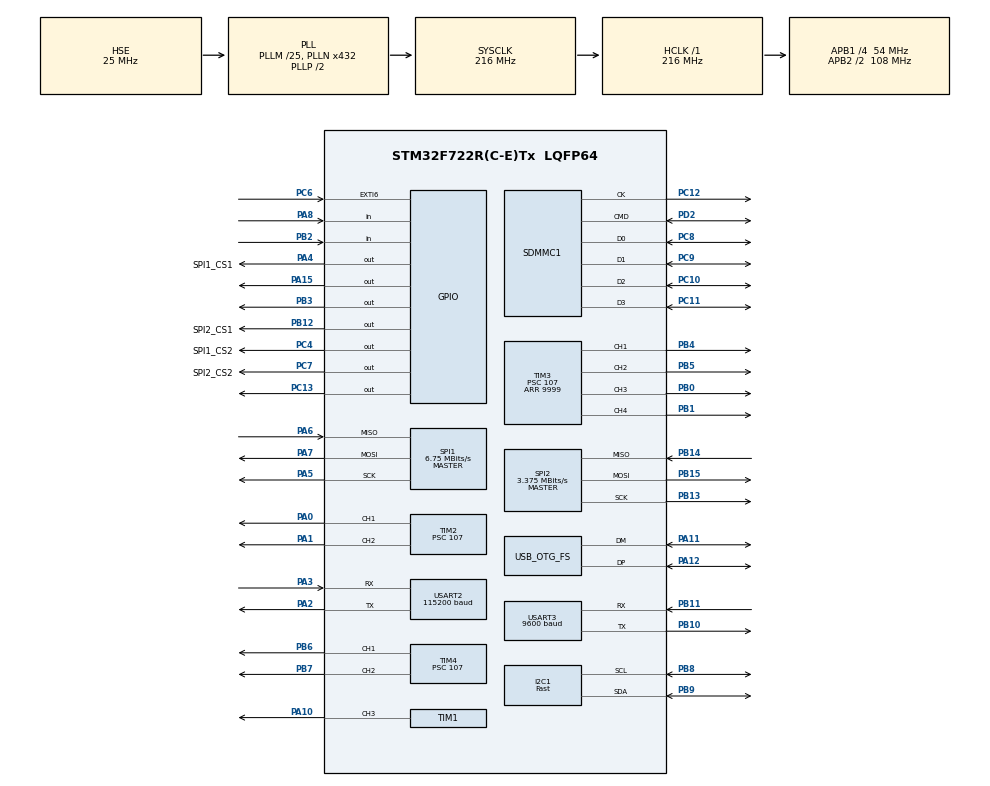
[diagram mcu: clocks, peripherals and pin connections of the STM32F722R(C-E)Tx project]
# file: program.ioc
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ADC1.Channel-13\#ChannelRegularConversion=ADC_CHANNEL_TEMPSENSOR
ADC1.NbrOfConversionFlag=1
ADC1.Rank-13\#ChannelRegularConversion=1
ADC1.SamplingTime-13\#ChannelRegularConversion=ADC_SAMPLETIME_3CYCLES
ADC1.master=1
CORTEX_M7.default_mode_Activation=1
Dma.I2C1_RX.1.Direction=DMA_PERIPH_TO_MEMORY
Dma.I2C1_RX.1.FIFOMode=DMA_FIFOMODE_DISABLE
Dma.I2C1_RX.1.Instance=DMA1_Stream0
Dma.I2C1_RX.1.MemDataAlignment=DMA_MDATAALIGN_BYTE
Dma.I2C1_RX.1.MemInc=DMA_MINC_ENABLE
Dma.I2C1_RX.1.Mode=DMA_NORMAL
Dma.I2C1_RX.1.PeriphDataAlignment=DMA_PDATAALIGN_BYTE
Dma.I2C1_RX.1.PeriphInc=DMA_PINC_DISABLE
Dma.I2C1_RX.1.Priority=DMA_PRIORITY_MEDIUM
Dma.I2C1_TX.7.Direction=DMA_MEMORY_TO_PERIPH
Dma.I2C1_TX.7.FIFOMode=DMA_FIFOMODE_DISABLE
Dma.I2C1_TX.7.Instance=DMA1_Stream7
Dma.I2C1_TX.7.MemDataAlignment=DMA_MDATAALIGN_BYTE
Dma.I2C1_TX.7.MemInc=DMA_MINC_ENABLE
Dma.I2C1_TX.7.Mode=DMA_NORMAL
Dma.I2C1_TX.7.PeriphDataAlignment=DMA_PDATAALIGN_BYTE
Dma.I2C1_TX.7.PeriphInc=DMA_PINC_DISABLE
Dma.I2C1_TX.7.Priority=DMA_PRIORITY_MEDIUM
Dma.Request0=SDMMC1
Dma.Request1=I2C1_RX
Dma.Request2=SPI1_RX
Dma.Request3=SPI2_RX
Dma.Request4=USART2_TX
Dma.Request5=SPI1_TX
Dma.Request6=SPI2_TX
Dma.Request7=I2C1_TX
Dma.SDMMC1.0.Direction=DMA_PERIPH_TO_MEMORY
Dma.SDMMC1.0.FIFOMode=DMA_FIFOMODE_ENABLE
Dma.SDMMC1.0.FIFOThreshold=DMA_FIFO_THRESHOLD_FULL
Dma.SDMMC1.0.Instance=DMA2_Stream6
Dma.SDMMC1.0.MemBurst=DMA_MBURST_INC4
Dma.SDMMC1.0.MemDataAlignment=DMA_MDATAALIGN_WORD
Dma.SDMMC1.0.MemInc=DMA_MINC_ENABLE
Dma.SDMMC1.0.Mode=DMA_PFCTRL
Dma.SDMMC1.0.PeriphBurst=DMA_PBURST_INC4
Dma.SDMMC1.0.PeriphDataAlignment=DMA_PDATAALIGN_WORD
Dma.SDMMC1.0.PeriphInc=DMA_PINC_DISABLE
Dma.SDMMC1.0.Priority=DMA_PRIORITY_LOW
Dma.SPI1_RX.2.Direction=DMA_PERIPH_TO_MEMORY
Dma.SPI1_RX.2.FIFOMode=DMA_FIFOMODE_DISABLE
Dma.SPI1_RX.2.Instance=DMA2_Stream0
Dma.SPI1_RX.2.MemDataAlignment=DMA_MDATAALIGN_BYTE
Dma.SPI1_RX.2.MemInc=DMA_MINC_ENABLE
Dma.SPI1_RX.2.Mode=DMA_NORMAL
Dma.SPI1_RX.2.PeriphDataAlignment=DMA_PDATAALIGN_BYTE
Dma.SPI1_RX.2.PeriphInc=DMA_PINC_DISABLE
Dma.SPI1_RX.2.Priority=DMA_PRIORITY_MEDIUM
Dma.SPI1_TX.5.Direction=DMA_MEMORY_TO_PERIPH
Dma.SPI1_TX.5.FIFOMode=DMA_FIFOMODE_DISABLE
Dma.SPI1_TX.5.Instance=DMA2_Stream5
Dma.SPI1_TX.5.MemDataAlignment=DMA_MDATAALIGN_BYTE
Dma.SPI1_TX.5.MemInc=DMA_MINC_ENABLE
Dma.SPI1_TX.5.Mode=DMA_NORMAL
Dma.SPI1_TX.5.PeriphDataAlignment=DMA_PDATAALIGN_BYTE
Dma.SPI1_TX.5.PeriphInc=DMA_PINC_DISABLE
Dma.SPI1_TX.5.Priority=DMA_PRIORITY_MEDIUM
Dma.SPI2_RX.3.Direction=DMA_PERIPH_TO_MEMORY
Dma.SPI2_RX.3.FIFOMode=DMA_FIFOMODE_DISABLE
Dma.SPI2_RX.3.Instance=DMA1_Stream3
Dma.SPI2_RX.3.MemDataAlignment=DMA_MDATAALIGN_BYTE
Dma.SPI2_RX.3.MemInc=DMA_MINC_ENABLE
Dma.SPI2_RX.3.Mode=DMA_NORMAL
Dma.SPI2_RX.3.PeriphDataAlignment=DMA_PDATAALIGN_BYTE
Dma.SPI2_RX.3.PeriphInc=DMA_PINC_DISABLE
Dma.SPI2_RX.3.Priority=DMA_PRIORITY_HIGH
Dma.SPI2_TX.6.Direction=DMA_MEMORY_TO_PERIPH
Dma.SPI2_TX.6.FIFOMode=DMA_FIFOMODE_DISABLE
Dma.SPI2_TX.6.Instance=DMA1_Stream4
Dma.SPI2_TX.6.MemDataAlignment=DMA_MDATAALIGN_BYTE
Dma.SPI2_TX.6.MemInc=DMA_MINC_ENABLE
Dma.SPI2_TX.6.Mode=DMA_NORMAL
Dma.SPI2_TX.6.PeriphDataAlignment=DMA_PDATAALIGN_BYTE
Dma.SPI2_TX.6.PeriphInc=DMA_PINC_DISABLE
Dma.SPI2_TX.6.Priority=DMA_PRIORITY_HIGH
Dma.USART2_TX.4.Direction=DMA_MEMORY_TO_PERIPH
Dma.USART2_TX.4.FIFOMode=DMA_FIFOMODE_DISABLE
Dma.USART2_TX.4.Instance=DMA1_Stream6
Dma.USART2_TX.4.MemDataAlignment=DMA_MDATAALIGN_BYTE
Dma.USART2_TX.4.MemInc=DMA_MINC_ENABLE
Dma.USART2_TX.4.Mode=DMA_NORMAL
Dma.USART2_TX.4.PeriphDataAlignment=DMA_PDATAALIGN_BYTE
Dma.USART2_TX.4.PeriphInc=DMA_PINC_DISABLE
Dma.USART2_TX.4.Priority=DMA_PRIORITY_MEDIUM
FATFS.BSP.number=1
FATFS0.BSP.STBoard=false
FATFS0.BSP.api=Unknown
FATFS0.BSP.instance=PA8
FATFS0.BSP.ip=GPIO
FATFS0.BSP.mode=Input
FATFS0.BSP.name=Detect_SDIO
FATFS0.BSP.solution=PA8
FREERTOS.BinarySemaphores01=icmDmaSem,Dynamic,NULL,Depleted;bmpDmaSem,Dynamic,NULL,Depleted;bmmDmaSem,Dynamic,NULL,Depleted;inaDmaSem,Dynamic,NULL,Depleted;flashDmaSem,Dynamic,NULL,Depleted;uart2TxDmaSem,Dynamic,NULL,Depleted;uart2RxSem,Dynamic,NULL,Depleted;pmwDmaSem,Dynamic,NULL,Depleted;i2c1DmaSem,Dynamic,NULL,Depleted
FREERTOS.Mutexes01=stateMutex,Dynamic,NULL,Available;spi1Mutex,Dynamic,NULL,Available;comTxMutex,Dynamic,NULL,Available;spi2Mutex,Dynamic,NULL,Available;i2c1Mutex,Dynamic,NULL,Available
FREERTOS.Queues01=loggerQueue,16,flight_log_t,0,Dynamic,NULL,NULL;telemetryQueue,4,telemetry_packet_t,0,Dynamic,NULL,NULL;transferQueue,1,uint8_t,0,Dynamic,NULL,NULL
FREERTOS.Tasks01=controlTask,48,2048,ControlTask,Default,NULL,Dynamic,NULL,NULL;commandTask,40,512,CommandTask,Default,NULL,Dynamic,NULL,NULL;loggerTask,32,256,LoggerTask,Default,NULL,Dynamic,NULL,NULL;telemetryTask,24,256,TelemetryTask,Default,NULL,Dynamic,NULL,NULL;transferTask,48,1024,TransferTask,Default,NULL,Dynamic,NULL,NULL
FREERTOS.configTOTAL_HEAP_SIZE=24576
FREERTOS.configUSE_NEWLIB_REENTRANT=1
I2C1.I2C_Speed_Mode=I2C_Fast
I2C1.Timing=0x6000030D
Mcu.Family=STM32F7
Mcu.Name=STM32F722R(C-E)Tx
Mcu.Package=LQFP64
NVIC.DMA1_Stream0_IRQn=true\:5\:0\:false\:false\:true\:true\:false\:true\:true
NVIC.DMA1_Stream3_IRQn=true\:5\:0\:false\:false\:true\:true\:false\:true\:true
NVIC.DMA1_Stream4_IRQn=true\:5\:0\:false\:false\:true\:true\:false\:true\:true
NVIC.DMA1_Stream6_IRQn=true\:5\:0\:false\:false\:true\:true\:false\:true\:true
NVIC.DMA1_Stream7_IRQn=true\:5\:0\:false\:false\:true\:true\:false\:true\:true
NVIC.DMA2_Stream0_IRQn=true\:5\:0\:false\:false\:true\:true\:false\:true\:true
NVIC.DMA2_Stream5_IRQn=true\:5\:0\:false\:false\:true\:true\:false\:true\:true
NVIC.DMA2_Stream6_IRQn=true\:5\:0\:false\:false\:true\:true\:false\:true\:true
NVIC.I2C1_ER_IRQn=true\:5\:0\:false\:false\:true\:true\:true\:true\:true
NVIC.I2C1_EV_IRQn=true\:5\:0\:false\:false\:true\:true\:true\:true\:true
NVIC.OTG_FS_IRQn=true\:5\:0\:false\:false\:true\:true\:false\:true\:true
NVIC.PriorityGroup=NVIC_PRIORITYGROUP_4
NVIC.SDMMC1_IRQn=true\:5\:0\:false\:false\:true\:true\:true\:true\:true
NVIC.SPI1_IRQn=true\:5\:0\:false\:false\:true\:true\:true\:true\:true
NVIC.SPI2_IRQn=true\:5\:0\:false\:false\:true\:true\:true\:true\:true
NVIC.TIM6_DAC_IRQn=true\:5\:0\:false\:false\:true\:true\:true\:true\:true
NVIC.TIM7_IRQn=true\:15\:0\:false\:false\:true\:false\:false\:true\:true
NVIC.TimeBase=TIM7_IRQn
NVIC.TimeBaseIP=TIM7
NVIC.USART2_IRQn=true\:5\:0\:false\:false\:true\:true\:true\:true\:true
PA0-WKUP.Signal=S_TIM2_CH1_ETR
PA1.Signal=S_TIM2_CH2
PA10.Signal=S_TIM1_CH3
PA11.Mode=Device_Only
PA11.Signal=USB_OTG_FS_DM
PA12.Mode=Device_Only
PA12.Signal=USB_OTG_FS_DP
PA13.Mode=Serial_Wire
PA13.Signal=SYS_JTMS-SWDIO
PA14.Mode=Serial_Wire
PA14.Signal=SYS_JTCK-SWCLK
PA15.Signal=GPIO_Output
PA2.Mode=Asynchronous
PA2.Signal=USART2_TX
PA3.Mode=Asynchronous
PA3.Signal=USART2_RX
PA4.GPIO_Label=SPI1_CS1
PA4.GPIO_Speed=GPIO_SPEED_FREQ_HIGH
PA4.PinState=GPIO_PIN_SET
PA4.Signal=GPIO_Output
PA5.Mode=Full_Duplex_Master
PA5.Signal=SPI1_SCK
PA6.Mode=Full_Duplex_Master
PA6.Signal=SPI1_MISO
PA7.Mode=Full_Duplex_Master
PA7.Signal=SPI1_MOSI
PA8.Signal=GPIO_Input
PB0.Signal=S_TIM3_CH3
PB1.Signal=S_TIM3_CH4
PB10.Mode=Asynchronous
PB10.Signal=USART3_TX
PB11.Mode=Asynchronous
PB11.Signal=USART3_RX
PB12.GPIO_Label=SPI2_CS1
PB12.GPIO_Speed=GPIO_SPEED_FREQ_HIGH
PB12.PinState=GPIO_PIN_SET
PB12.Signal=GPIO_Output
PB13.Mode=Full_Duplex_Master
PB13.Signal=SPI2_SCK
PB14.Mode=Full_Duplex_Master
PB14.Signal=SPI2_MISO
PB15.Mode=Full_Duplex_Master
PB15.Signal=SPI2_MOSI
PB2.Signal=GPIO_Input
PB3.Signal=GPIO_Output
PB4.Signal=S_TIM3_CH1
PB5.Signal=S_TIM3_CH2
PB6.Signal=S_TIM4_CH1
PB7.Signal=S_TIM4_CH2
PB8.Mode=I2C
PB8.Signal=I2C1_SCL
PB9.Mode=I2C
PB9.Signal=I2C1_SDA
PC10.Mode=SD_4_bits_Wide_bus
PC10.Signal=SDMMC1_D2
PC11.Mode=SD_4_bits_Wide_bus
PC11.Signal=SDMMC1_D3
PC12.Mode=SD_4_bits_Wide_bus
PC12.Signal=SDMMC1_CK
PC13.Signal=GPIO_Output
PC4.GPIO_Label=SPI1_CS2
PC4.GPIO_Speed=GPIO_SPEED_FREQ_HIGH
PC4.PinState=GPIO_PIN_SET
PC4.Signal=GPIO_Output
PC6.Signal=GPXTI6
PC7.GPIO_Label=SPI2_CS2
PC7.GPIO_Speed=GPIO_SPEED_FREQ_HIGH
PC7.PinState=GPIO_PIN_SET
PC7.Signal=GPIO_Output
PC8.Mode=SD_4_bits_Wide_bus
PC8.Signal=SDMMC1_D0
PC9.Mode=SD_4_bits_Wide_bus
PC9.Signal=SDMMC1_D1
PD2.Mode=SD_4_bits_Wide_bus
PD2.Signal=SDMMC1_CMD
PH0-OSC_IN.Mode=HSE-External-Oscillator
PH0-OSC_IN.Signal=RCC_OSC_IN
PH1-OSC_OUT.Mode=HSE-External-Oscillator
PH1-OSC_OUT.Signal=RCC_OSC_OUT
ProjectManager.HeapSize=0x1000
ProjectManager.StackSize=0x800
ProjectManager.TargetToolchain=STM32CubeIDE
RCC.AHBFreq_Value=216000000
RCC.APB1CLKDivider=RCC_HCLK_DIV4
RCC.APB1Freq_Value=54000000
RCC.APB1TimFreq_Value=108000000
RCC.APB2CLKDivider=RCC_HCLK_DIV2
RCC.APB2Freq_Value=108000000
RCC.APB2TimFreq_Value=216000000
RCC.CortexFreq_Value=216000000
RCC.HCLKFreq_Value=216000000
RCC.HSE_VALUE=25000000
RCC.HSI_VALUE=16000000
RCC.LSE_VALUE=32768
RCC.PLLM=25
RCC.PLLN=432
RCC.PLLQ=9
RCC.SDMMCClockSelection=RCC_SDMMC1CLKSOURCE_CLK48
RCC.SYSCLKFreq_VALUE=216000000
RCC.SYSCLKSource=RCC_SYSCLKSOURCE_PLLCLK
RCC.USBFreq_Value=48000000
RCC.VCOOutputFreq_Value=432000000
SDMMC1.ClockDiv=1
SDMMC1.HardwareFlowControl=SDMMC_HARDWARE_FLOW_CONTROL_ENABLE
SH.S_TIM1_CH3.0=TIM1_CH3,PWM Generation3 CH3
SH.S_TIM2_CH1_ETR.0=TIM2_CH1,PWM Generation1 CH1
SH.S_TIM2_CH2.0=TIM2_CH2,PWM Generation2 CH2
SH.S_TIM3_CH1.0=TIM3_CH1,PWM Generation1 CH1
SH.S_TIM3_CH2.0=TIM3_CH2,PWM Generation2 CH2
SH.S_TIM3_CH3.0=TIM3_CH3,PWM Generation3 CH3
SH.S_TIM3_CH4.0=TIM3_CH4,PWM Generation4 CH4
SH.S_TIM4_CH1.0=TIM4_CH1,PWM Generation1 CH1
SH.S_TIM4_CH2.0=TIM4_CH2,PWM Generation2 CH2
SPI1.BaudRatePrescaler=SPI_BAUDRATEPRESCALER_16
SPI1.CLKPhase=SPI_PHASE_2EDGE
SPI1.CLKPolarity=SPI_POLARITY_HIGH
SPI1.CalculateBaudRate=6.75 MBits/s
SPI1.DataSize=SPI_DATASIZE_8BIT
SPI1.Direction=SPI_DIRECTION_2LINES
SPI1.Mode=SPI_MODE_MASTER
SPI1.VirtualType=VM_MASTER
SPI2.BaudRatePrescaler=SPI_BAUDRATEPRESCALER_16
SPI2.CLKPhase=SPI_PHASE_1EDGE
SPI2.CLKPolarity=SPI_POLARITY_LOW
SPI2.CalculateBaudRate=3.375 MBits/s
SPI2.DataSize=SPI_DATASIZE_8BIT
SPI2.Direction=SPI_DIRECTION_2LINES
SPI2.Mode=SPI_MODE_MASTER
SPI2.VirtualType=VM_MASTER
TIM1.Channel-PWM\ Generation3\ CH3=TIM_CHANNEL_3
TIM1.Period=19999
TIM1.Prescaler=107
TIM2.Channel-PWM\ Generation1\ CH1=TIM_CHANNEL_1
TIM2.Channel-PWM\ Generation2\ CH2=TIM_CHANNEL_2
TIM2.OCFastMode_PWM-PWM\ Generation1\ CH1=TIM_OCFAST_DISABLE
TIM2.Period=2499
TIM2.Prescaler=107
TIM3.Channel-PWM\ Generation1\ CH1=TIM_CHANNEL_1
TIM3.Channel-PWM\ Generation2\ CH2=TIM_CHANNEL_2
TIM3.Channel-PWM\ Generation3\ CH3=TIM_CHANNEL_3
TIM3.Channel-PWM\ Generation4\ CH4=TIM_CHANNEL_4
TIM3.OCFastMode_PWM-PWM\ Generation1\ CH1=TIM_OCFAST_DISABLE
TIM3.Period=9999
TIM3.Prescaler=107
TIM4.Channel-PWM\ Generation1\ CH1=TIM_CHANNEL_1
TIM4.Channel-PWM\ Generation2\ CH2=TIM_CHANNEL_2
TIM4.OCFastMode_PWM-PWM\ Generation1\ CH1=TIM_OCFAST_DISABLE
TIM4.Period=19999
TIM4.Prescaler=107
TIM6.Period=9999
TIM6.Prescaler=107
USART2.BaudRate=115200
USART2.VirtualMode-Asynchronous=VM_ASYNC
USART3.BaudRate=9600
USART3.VirtualMode-Asynchronous=VM_ASYNC
USB_DEVICE.CLASS_NAME_FS=CDC
USB_DEVICE.VirtualMode-CDC_FS=Cdc
USB_DEVICE.VirtualModeFS=Cdc_FS
USB_OTG_FS.VirtualMode=Device_Only
USB_OTG_FS.battery_charging_enable=DISABLE
VP_ADC1_TempSens_Input.Mode=IN-TempSens
VP_ADC1_Vref_Input.Mode=IN-Vrefint
VP_FATFS_VS_SDIO.Mode=SDIO
VP_FREERTOS_VS_CMSIS_V2.Mode=CMSIS_V2
VP_SYS_VS_tim7.Mode=TIM7
VP_TIM2_VS_ClockSourceINT.Mode=Internal
VP_TIM3_VS_ClockSourceINT.Mode=Internal
VP_TIM4_VS_ClockSourceINT.Mode=Internal
VP_TIM6_VS_ClockSourceINT.Mode=Enable_Timer
VP_USB_DEVICE_VS_USB_DEVICE_CDC_FS.Mode=CDC_FS
board=custom

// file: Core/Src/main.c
/* USER CODE BEGIN Header */
/**
  ******************************************************************************
  * @file           : main.c
  * @brief          : Main program body
  ******************************************************************************
  * @attention
  *
  * Copyright (c) 2026 STMicroelectronics.
  * All rights reserved.
  *
  * This software is licensed under terms that can be found in the LICENSE file
  * in the root directory of this software component.
  * If no LICENSE file comes with this software, it is provided AS-IS.
  *
  ******************************************************************************
  */
/* USER CODE END Header */
#include "main.h"
#include "cmsis_os.h"
#include "adc.h"
#include "dma.h"
#include "fatfs.h"
#include "i2c.h"
#include "sdmmc.h"
#include "spi.h"
#include "tim.h"
#include "usart.h"
#include "usb_device.h"
#include "gpio.h"

/* USER CODE BEGIN Includes */
#include "global.h"
/* USER CODE END Includes */

/* USER CODE BEGIN PV */

#if 1 // GLOBAL VARIABLES
bmm150_data_t bmm150_data;
bmp388_data_t bmp388_data;
icm42688p_data_t icm42688p_data;
ina226_data_t ina226_data;
FATFS fs;
FIL fil;
FRESULT res;
uint8_t com_receive_buf[128] = {0};
uint8_t com_transmit_buf[128] = {0};
note_t melody[] = {
    {NOTE_C5, EIGHTH}, {NOTE_D5, EIGHTH}, {NOTE_E5, EIGHTH}, {NOTE_G5, EIGHTH},
    {NOTE_E5, EIGHTH}, {NOTE_G5, QUARTER}, {NOTE_C6, HALF},
};
uint8_t melody_len = (sizeof(melody) / sizeof(melody[0]));

FusionAhrs ahrs;
FusionBias bias;
FusionMatrix gyro_misalignment = {{1.0f, 0.0f, 0.0f, 0.0f, 1.0f, 0.0f, 0.0f, 0.0f, 1.0f}};
FusionVector gyro_sensitivity = {{1.0f, 1.0f, 1.0f}};
FusionVector gyro_offset = {{0.0f, 0.0f, 0.0f}};
FusionMatrix accel_misalignement = {{1.0f, 0.0f, 0.0f, 0.0f, 1.0f, 0.0f, 0.0f, 0.0f, 1.0f}};
FusionVector accel_sensitivity = {{1.0f, 1.0f, 1.0f}};
FusionVector accel_offset = {{0.0f, 0.0f, 0.0f}};
FusionMatrix mag_softIronMatrix = {{0.940f, 0.041f, 0.0f, 0.041f, 1.027f, 0.006f, 0.0f, 0.006f, 1.047f}};
FusionVector mag_hardIronOffset = {{-7.37f, 3.12f, 16.56f}};

FusionAhrsSettings settings = {
	.convention = FusionConventionNed,
	.gain = 0.5f,
	.gyroscopeRange = 500.0f,
	.accelerationRejection = 8.0f,
	.magneticRejection = 10.0f,
};
FusionVector gyro;
FusionVector accel;
FusionVector mag;
FusionEuler ori;
FusionVector lin_accel;
FusionVector vel = {{0, 0, 0}};
FusionVector pos = {{0, 0, 0}};

kalman_t kf_altitude;
float altitude_offset = 0;

lpf_t lpf_altitude;
lpf_t lpf_voltage;
lpf_t lpf_velx;
lpf_t lpf_vely;

lqr_t lqr;
float u_min[] = {-0.149066f, -0.149066f, -0.1, -HOVER_THRUST};
float u_max[] = { 0.149066f,  0.149066f, 0.1, 0.05f * G};
float x_ref[] = {0.0f, 0.0f, 0.0f, 0.0f, 0.0f, 0.0f, 0.0f, 0.0f, 0.0f, 0.0f, 0.0f, 0.0f};
float cmd_ref[] = {0.0f, 0.0f, 0.0f};
float pz_integral = 0;
float rx_integral = 0;
float ry_integral = 0;
float rz_integral = 0;
float rz_offset = 0;
float rz_prev_wrapped = 0.0f;
float rz_unwrapped = 0.0f;
volatile bool rz_unwrap_init = false;
volatile bool dt_init = false;

float ref_rx_offset = -4.0f; // hard coded offsets
float ref_ry_offset = 7.0f;  // hard coded offsets
float ref_rz_offset = 0;
float ref_pz_offset = 0;

volatile spi2_pending_t spi2_pending = SPI2_PENDING_NONE;
volatile i2c1_pending_t i2c1_pending = I2C1_PENDING_NONE;

drone_state_t drone_state = DRONE_DISARMED;

uint32_t flash_write_address = 0x000000;
uint32_t flash_max_address = 0x1000000;
#endif // GLOBAL VARIABLES

#if 1 // LOCAL VARIABLES
uint16_t flash_buf_idx = 0;
uint8_t  flash_page_buffer[256];
const float K[LQR_MAX_INPUTS][LQR_MAX_STATES] = {
    {-1.14198845f, 0.00000000f, 0.00000000f, 0.00000000f, -0.29207114f, 0.00000000f, 0.00000000f, 0.00000000f, -0.29505944f, 0.00000000f, 0.00000000f, 0.00000000f},
    {0.00000000f, 1.14198845f, 0.00000000f, 0.00000000f, 0.00000000f, 0.29207114f, 0.00000000f, 0.00000000f, 0.00000000f, 0.29505944f, 0.00000000f, 0.00000000f},
    {0.00000000f, 0.00000000f, 0.06454058f, 0.00000000f, 0.00000000f, 0.00000000f, 0.57378372f, 0.00000000f, 0.00000000f, 0.00000000f, 0.00238777f, 0.00000000f},
	{0.00000000f, 0.00000000f, 0.00000000f, 1.73874813f, 0.00000000f, 0.00000000f, 0.00000000f, 1.23067720f, 0.00000000f, 0.00000000f, 0.00000000f, 0.04408133f},
};
float  Q[] = {0.05f, // acceleration
             0.1f, // velocity
             0.3f}; // position

float R[] = {0.15f, // imu noise
             0.15f, // barometer noise
			 0.005f}; // tof noise

kalman_t kf_vel_x;
kalman_t kf_vel_y;

float Q_vel[] = {0.05f,  // acceleration — reused from kf_altitude's tuning, same physical sensor
                  0.5f}; // velocity

float R_vel[] = {0.15f, // accelerometer noise
                  0.001f}; // optical flow sensor noise

float x0_vel[] = {0.0f, 0.0f};

pid_t vel_pid_x = {
	.kp =  -0.140f,
	.ki = -0.040f,
	.kd = -0.008f,
	.output_min = -0.2f,
	.output_max =  0.2f,
	.integral_min = -2.5f,
	.integral_max =  2.5f,
	.d_filter_alpha = 0.1f,
	.decimation_factor = 5, // division factor from the P and I update loop to the output loop
};
pid_t vel_pid_y = {
	.kp =  0.140f,
	.ki = 0.040f,
	.kd = 0.008f,
	.output_min = -0.2f,
	.output_max =  0.2f,
	.integral_min = -2.5f,
	.integral_max =  2.5f,
	.d_filter_alpha = 0.1f,
	.decimation_factor = 5,
};
pid_t pos_p_x = {
	.kp =  0.5f,
	.output_min = -0.5f,
	.output_max =  0.5f,
	.decimation_factor = 10, // division factor from the P and I update loop to the output loop
};

pid_t pos_p_y = {
	.kp =  0.5f,
	.output_min = -0.5f,
	.output_max =  0.5f,
	.decimation_factor = 10,
};
float x0[] = {0.0f, 0.0f, 0.0f};
#endif // LOCAL VARIABLES

#if 1 // DRIVER CONFIG
pmw3901_data_t pmw3901_data;
pmw3901_config_t pmw3901_conf = {
    .hspi    = &hspi2,
    .cs_port = SPI2_CS2_GPIO_Port,
    .cs_pin  = SPI2_CS2_Pin,
};

uint16_t vl53l1x_dev = 0x52;
servo_config_t servox_conf = {
	.pwm_timer = &htim3,
	.pwm_channel = TIM_CHANNEL_1,
	.offset = 25,
};
servo_config_t servoy_conf = {
	.pwm_timer = &htim3,
	.pwm_channel = TIM_CHANNEL_4,
	.offset = 20,
};
motor_config_t motor1_conf = {
	.pwm_timer = &htim2,
	.pwm_channel = TIM_CHANNEL_1,
};
motor_config_t motor2_conf = {
	.pwm_timer = &htim2,
	.pwm_channel = TIM_CHANNEL_2,
};
bmm150_config_t bmm150_conf = {
	.iface    = BMM150_IFACE_I2C,
	.hi2c     = &hi2c1,
	.i2c_addr = BMM150_I2C_ADDR_ALT3,
	.hspi     = NULL,
	.cs_port  = NULL,
	.cs_pin   = 0,
	.op_ctrl  = BMM150_OPMODE_NORMAL | BMM150_ODR_10HZ,
	.rep_xy   = 0x01U,
	.rep_z    = 0x06U,
};
bmp388_config_t bmp388_conf = {
    .iface    = BMP388_IFACE_SPI,
    .hspi     = &hspi1,
    .cs_port  = SPI1_CS1_GPIO_Port,
    .cs_pin   = SPI1_CS1_Pin,
    .prs_cfg  = BMP388_ODR_50HZ | BMP388_OSR_x8,
    .tmp_cfg  = BMP388_ODR_50HZ | BMP388_OSR_x1,
    .mode     = BMP388_MODE_NORMAL,
    .sea_level_hpa = 1013.25f,
};
icm42688p_config_t icm42688p_conf = {
    .iface         = ICM42688P_IFACE_SPI,
    .hspi          = &hspi2,
    .cs_port       = SPI2_CS1_GPIO_Port,
    .cs_pin        = SPI2_CS1_Pin,
    .hi2c          = NULL,
    .i2c_addr      = 0,
    .gyro_config  = ICM42688P_GYRO_FS_500DPS  | ICM42688P_ODR_1760HZ,
    .accel_config = ICM42688P_ACCEL_FS_8G     | ICM42688P_ODR_1760HZ,
    .acc_scale     = ICM42688P_ACC_SCALE_8G,
    .gyro_scale    = ICM42688P_GYRO_SCALE_500DPS,
};
ina226_config_t ina226_conf = {
	.hi2c          = &hi2c1,
	.i2c_addr      = INA226_I2C_ADDR(0, 0),
	.config_reg    = (INA226_AVG_1 | INA226_VBUS_CT_140US | INA226_VSH_CT_140US | INA226_MODE_SHUNT_BUS_CONT),
	.current_lsb_A = 0.001f,
	.r_shunt_ohm   = 0.002f
};
w25q128_config_t w25q128_conf = {
	.hspi    = &hspi1,
	.cs_port = SPI1_CS2_GPIO_Port,
	.cs_pin  = SPI1_CS2_Pin
};
com_config_t com_conf = {
	.com_method = COM_LORA,
	.m0m1_pin = GPIO_PIN_3,
	.m0m1_port = GPIOB,
	.uart    = &huart2,
	.receive_buf = com_receive_buf,
	.transmit_buf = com_transmit_buf,
	.timeout = 1000,
};
signal_config_t signal_conf = {
	.led_port = GPIOC,
	.led_pin = GPIO_PIN_13,
	.buzzer_htim = &htim1,
	.buzzer_channel = TIM_CHANNEL_3,
};
#endif // DRIVER CONFIG

/* USER CODE END PV */

void SystemClock_Config(void);
static void MPU_Config(void);
void MX_FREERTOS_Init(void);

/* USER CODE BEGIN 0 */
static uint32_t g_log_field_mask = LOG_MASK_ALL;

static uint16_t flight_log_serialize(uint8_t *buf, const flight_log_t *log, uint32_t mask) {
	uint16_t idx = 0;
	memcpy(&buf[idx], &mask, 4); idx += 4;
	memcpy(&buf[idx], &log->timestamp_ms, 4); idx += 4;
	buf[idx++] = log->drone_state;

	if (mask & LOG_FIELD_ACCEL)   { memcpy(&buf[idx], &log->accel, sizeof(FusionVector)); idx += sizeof(FusionVector); }
	if (mask & LOG_FIELD_GYRO)    { memcpy(&buf[idx], &log->gyro,  sizeof(FusionVector)); idx += sizeof(FusionVector); }
	if (mask & LOG_FIELD_MAG)     { memcpy(&buf[idx], &log->mag,   sizeof(FusionVector)); idx += sizeof(FusionVector); }
	if (mask & LOG_FIELD_BARO)    { memcpy(&buf[idx], &log->baro_altitude_m, 4); idx += 4; }
	if (mask & LOG_FIELD_TOF)     { memcpy(&buf[idx], &log->tof_altitude_m,  4); idx += 4; }
	if (mask & LOG_FIELD_FLOW)    { memcpy(&buf[idx], &log->flow_dx, 4); idx += 4;
	                                 memcpy(&buf[idx], &log->flow_dy, 4); idx += 4; }
	if (mask & LOG_FIELD_VOLTAGE) { memcpy(&buf[idx], &log->voltage, 4); idx += 4; }
	if (mask & LOG_FIELD_ORI) {
		memcpy(&buf[idx], &log->rx, 4); idx += 4;
		memcpy(&buf[idx], &log->ry, 4); idx += 4;
		memcpy(&buf[idx], &log->rz, 4); idx += 4;
	}
	if (mask & LOG_FIELD_POS) {
		memcpy(&buf[idx], &log->pos_x, 4); idx += 4;
		memcpy(&buf[idx], &log->pos_y, 4); idx += 4;
		memcpy(&buf[idx], &log->pos_z, 4); idx += 4;
	}
	if (mask & LOG_FIELD_POS_P)   { memcpy(&buf[idx], &log->pos_p_out_x, 4); idx += 4;
	                                 memcpy(&buf[idx], &log->pos_p_out_y, 4); idx += 4; }
	if (mask & LOG_FIELD_VEL_PID) { memcpy(&buf[idx], &log->vel_pid_out_x, 4); idx += 4;
	                                 memcpy(&buf[idx], &log->vel_pid_out_y, 4); idx += 4; }
	if (mask & LOG_FIELD_LQR)     { memcpy(&buf[idx], log->lqr_u, sizeof(log->lqr_u)); idx += sizeof(log->lqr_u); }
	if (mask & LOG_FIELD_SERVO)   { memcpy(&buf[idx], &log->servo_x, 4); idx += 4;
	                                 memcpy(&buf[idx], &log->servo_y, 4); idx += 4; }
	if (mask & LOG_FIELD_MOTOR)   { memcpy(&buf[idx], &log->motor1, 4); idx += 4;
	                                 memcpy(&buf[idx], &log->motor2, 4); idx += 4; }

	return idx;
}

/* Returns false if this record slot is erased/unwritten flash (end of valid
 * data in this page). Otherwise populates *out (fields absent from this
 * record's own mask are left zeroed) and *record_len (bytes consumed). */
static bool flight_log_deserialize(const uint8_t *buf, uint16_t buf_remaining, flight_log_t *out, uint16_t *record_len) {
	if (buf_remaining < 9) return false;

	uint32_t mask;
	memcpy(&mask, &buf[0], 4);
	if (mask == LOG_MASK_ERASED) return false;

	memset(out, 0, sizeof(*out));
	uint16_t idx = 4;
	memcpy(&out->timestamp_ms, &buf[idx], 4); idx += 4;
	out->drone_state = buf[idx++];

	if (mask & LOG_FIELD_ACCEL) { memcpy(&out->accel, &buf[idx], sizeof(FusionVector)); idx += sizeof(FusionVector); }
	if (mask & LOG_FIELD_GYRO)  { memcpy(&out->gyro,  &buf[idx], sizeof(FusionVector)); idx += sizeof(FusionVector); }
	if (mask & LOG_FIELD_MAG)   { memcpy(&out->mag,   &buf[idx], sizeof(FusionVector)); idx += sizeof(FusionVector); }
	if (mask & LOG_FIELD_BARO)  { memcpy(&out->baro_altitude_m, &buf[idx], 4); idx += 4; }
	if (mask & LOG_FIELD_TOF)   { memcpy(&out->tof_altitude_m,  &buf[idx], 4); idx += 4; }
	if (mask & LOG_FIELD_FLOW)  { memcpy(&out->flow_dx, &buf[idx], 4); idx += 4;
	                               memcpy(&out->flow_dy, &buf[idx], 4); idx += 4; }
	if (mask & LOG_FIELD_VOLTAGE) { memcpy(&out->voltage, &buf[idx], 4); idx += 4; }
	if (mask & LOG_FIELD_ORI) {
		memcpy(&out->rx, &buf[idx], 4); idx += 4;
		memcpy(&out->ry, &buf[idx], 4); idx += 4;
		memcpy(&out->rz, &buf[idx], 4); idx += 4;
	}
	if (mask & LOG_FIELD_POS) {
		memcpy(&out->pos_x, &buf[idx], 4); idx += 4;
		memcpy(&out->pos_y, &buf[idx], 4); idx += 4;
		memcpy(&out->pos_z, &buf[idx], 4); idx += 4;
	}
	if (mask & LOG_FIELD_POS_P)   { memcpy(&out->pos_p_out_x, &buf[idx], 4); idx += 4;
	                                 memcpy(&out->pos_p_out_y, &buf[idx], 4); idx += 4; }
	if (mask & LOG_FIELD_VEL_PID) { memcpy(&out->vel_pid_out_x, &buf[idx], 4); idx += 4;
	                                 memcpy(&out->vel_pid_out_y, &buf[idx], 4); idx += 4; }
	if (mask & LOG_FIELD_LQR)     { memcpy(out->lqr_u, &buf[idx], sizeof(out->lqr_u)); idx += sizeof(out->lqr_u); }
	if (mask & LOG_FIELD_SERVO)   { memcpy(&out->servo_x, &buf[idx], 4); idx += 4;
	                                 memcpy(&out->servo_y, &buf[idx], 4); idx += 4; }
	if (mask & LOG_FIELD_MOTOR)   { memcpy(&out->motor1, &buf[idx], 4); idx += 4;
	                                 memcpy(&out->motor2, &buf[idx], 4); idx += 4; }

	*record_len = idx;
	return true;
}

void log_to_flash(flight_log_t *log) {
	if (flash_write_address >= flash_max_address) {
		return;
	}

	uint8_t rec_buf[FLIGHT_LOG_MAX_RECORD_SIZE];
	uint16_t rec_len = flight_log_serialize(rec_buf, log, g_log_field_mask);

	if (flash_buf_idx + rec_len > 256) {
		memset(&flash_page_buffer[flash_buf_idx], 0xFF, 256 - flash_buf_idx);

		w25q128_data_t wdata = { .buf = flash_page_buffer, .len = 256 };
		if (w25q128_write_dma(flash_write_address, &wdata, flash_dma_complete_cb) == HAL_OK) {
			osSemaphoreAcquire(flashDmaSemHandle, W25Q128_TIMEOUT_PAGE_PROGRAM_MS);
		}
		w25q128_wait_busy(W25Q128_TIMEOUT_PAGE_PROGRAM_MS);

		flash_write_address += 256;
		flash_buf_idx = 0;

		if (flash_write_address >= flash_max_address) {
			return;
		}
	}

	memcpy(&flash_page_buffer[flash_buf_idx], rec_buf, rec_len);
	flash_buf_idx += rec_len;
}
uint8_t transfer_logs_to_sd(void) {
	uint32_t read_address = 0x000000;
	uint8_t read_page_buffer[256];
	flight_log_t log_packet;
	char csv_line[320];
	UINT bytes_written;

	if (flash_write_address == 0x000000 && flash_buf_idx == 0) {
		return 0;
	}

	res = f_mount(&fs, "", 1);
	if (res != FR_OK) {
		return 0;
	}

	res = f_open(&fil, "flight.csv", FA_WRITE | FA_CREATE_ALWAYS);
	if (res != FR_OK) {
		f_mount(NULL, "", 0);
		return 0;
	}

	const char* header =
		"timestamp_ms,state,"
		"accel_x,accel_y,accel_z,gyro_x,gyro_y,gyro_z,mag_x,mag_y,mag_z,"
		"baro_alt,tof_alt,flow_dx,flow_dy,voltage,"
		"rx,ry,rz,pos_x,pos_y,pos_z,"
		"pos_p_x,pos_p_y,vel_pid_x,vel_pid_y,"
		"lqr_u0,lqr_u1,lqr_u2,lqr_u3,"
		"servo_x,servo_y,motor1,motor2\n";
	res = f_write(&fil, header, strlen(header), &bytes_written);
	if (res != FR_OK || bytes_written != strlen(header)) {
		f_close(&fil);
		f_mount(NULL, "", 0);
		return 0;
	}

	if (flash_buf_idx > 0) {
		memset(&flash_page_buffer[flash_buf_idx], 0xFF, 256 - flash_buf_idx);

		if (w25q128_write(flash_write_address, flash_page_buffer, 256) != HAL_OK) {
			f_close(&fil);
			f_mount(NULL, "", 0);
			return 0;
		}
		w25q128_wait_busy(W25Q128_TIMEOUT_PAGE_PROGRAM_MS);
		flash_write_address += 256;
	}

	while (read_address < flash_write_address) {
		w25q128_data_t read_data = { .buf = read_page_buffer, .len = 256 };

		if (w25q128_read(read_address, &read_data) != HAL_OK) {
			break;
		}

		uint16_t offset = 0;
		while (offset < 256) {
			uint16_t record_len = 0;
			if (!flight_log_deserialize(&read_page_buffer[offset], 256 - offset, &log_packet, &record_len)) {
				break;   // erased/unwritten from here on within this page
			}

			int len = snprintf(csv_line, sizeof(csv_line),
				"%lu,%u,"
				"%.4f,%.4f,%.4f,%.4f,%.4f,%.4f,%.4f,%.4f,%.4f,"
				"%.3f,%.3f,%.3f,%.3f,%.3f,"
				"%.4f,%.4f,%.4f,%.3f,%.3f,%.3f,"
				"%.4f,%.4f,%.4f,%.4f,"
				"%.4f,%.4f,%.4f,%.4f,"
				"%.3f,%.3f,%.3f,%.3f\n",
				log_packet.timestamp_ms, log_packet.drone_state,
				log_packet.accel.axis.x, log_packet.accel.axis.y, log_packet.accel.axis.z,
				log_packet.gyro.axis.x,  log_packet.gyro.axis.y,  log_packet.gyro.axis.z,
				log_packet.mag.axis.x,   log_packet.mag.axis.y,   log_packet.mag.axis.z,
				log_packet.baro_altitude_m, log_packet.tof_altitude_m,
				log_packet.flow_dx, log_packet.flow_dy, log_packet.voltage,
				log_packet.rx, log_packet.ry, log_packet.rz,
				log_packet.pos_x, log_packet.pos_y, log_packet.pos_z,
				log_packet.pos_p_out_x, log_packet.pos_p_out_y,
				log_packet.vel_pid_out_x, log_packet.vel_pid_out_y,
				log_packet.lqr_u[0], log_packet.lqr_u[1], log_packet.lqr_u[2], log_packet.lqr_u[3],
				log_packet.servo_x, log_packet.servo_y, log_packet.motor1, log_packet.motor2);

			if (len > 0 && (size_t)len < sizeof(csv_line)) {
				f_write(&fil, csv_line, len, &bytes_written);
			}

			offset += record_len;
		}

		read_address += 256;
	}

	f_close(&fil);
	f_mount(NULL, "", 0);
	return 1;
}

void sys_init() {
	servo_init(&servox_conf);
	servo_init(&servoy_conf);
	motor_init(&motor1_conf);
	motor_init(&motor2_conf);
	com_init(&com_conf);
	com_receive_it_start(&com_conf);
	signal_init(&signal_conf);
	bmm150_init(&bmm150_conf);
	bmp388_init(&bmp388_conf);
	icm42688p_init(&icm42688p_conf);
	ina226_init(&ina226_conf);
	w25q128_init(&w25q128_conf);
	pmw3901_init(&pmw3901_conf);
	VL53L1X_SensorInit(vl53l1x_dev);
	VL53L1X_SetDistanceMode(vl53l1x_dev, 1); // distance mode 1:short, 2:long
	VL53L1X_SetTimingBudgetInMs(vl53l1x_dev, 20);
	VL53L1X_SetInterMeasurementInMs(vl53l1x_dev, 20);
	VL53L1X_StartRanging(vl53l1x_dev);

	FusionAhrsInitialise(&ahrs); // fusion initialization
	FusionAhrsSetSettings(&ahrs, &settings);
	FusionBiasInitialise(&bias);
	FusionBiasSettings bias_settings = fusionBiasDefaultSettings;
	bias_settings.sampleRate = 100;
	FusionBiasSetSettings(&bias, &bias_settings);

	// calibrate accelerometer & gyroscope
	int i = 0;
	int ITERATION = 30;

	FusionVector accel_sum = {0};
	for (i = 0; i < ITERATION; i++) {
		icm42688p_read(&icm42688p_data);
		accel_sum.axis.x += icm42688p_data.accel_x_g;
		accel_sum.axis.y += icm42688p_data.accel_y_g;
		accel_sum.axis.z += icm42688p_data.accel_z_g;
		gyro_offset.axis.x += icm42688p_data.gyro_x_dps;
		gyro_offset.axis.y += icm42688p_data.gyro_y_dps;
		gyro_offset.axis.z += icm42688p_data.gyro_z_dps;
		HAL_Delay(100);
	}

	accel_sum   = FusionVectorScale(accel_sum, 1.0f / ITERATION);

	float accel_mag = sqrtf(accel_sum.axis.x * accel_sum.axis.x + accel_sum.axis.y * accel_sum.axis.y + accel_sum.axis.z * accel_sum.axis.z);
	float scale = 1.0f / accel_mag;

	accel_sensitivity = (FusionVector) {{scale, scale, scale}};
	gyro_offset = FusionVectorScale(gyro_offset, 1.0f / ITERATION);

	const float CONVERGE_DT = 0.01f;
	const int   MAX_CONVERGE_ITERATIONS = 500;

	i = 0;
	while (FusionAhrsGetFlags(&ahrs).startup && (i < MAX_CONVERGE_ITERATIONS)) {
		icm42688p_read(&icm42688p_data);
		bmm150_read(&bmm150_data);

		gyro  = (FusionVector) {{icm42688p_data.gyro_x_dps,  icm42688p_data.gyro_y_dps,  icm42688p_data.gyro_z_dps}};
		accel = (FusionVector) {{icm42688p_data.accel_x_g,   icm42688p_data.accel_y_g,   icm42688p_data.accel_z_g}};
		gyro  = FusionModelInertial(gyro,  gyro_misalignment,  gyro_sensitivity,  gyro_offset);
		accel = FusionModelInertial(accel, accel_misalignement, accel_sensitivity, accel_offset);
		gyro  = FusionBiasUpdate(&bias, gyro);

		mag = (FusionVector) {{bmm150_data.mag_x_uT, bmm150_data.mag_y_uT, bmm150_data.mag_z_uT}};
		mag = FusionModelMagnetic(mag, mag_softIronMatrix, mag_hardIronOffset);

		FusionAhrsUpdate(&ahrs, gyro, accel, mag, CONVERGE_DT);

		HAL_Delay(10);
		i++;
	}

	if (FusionAhrsGetFlags(&ahrs).startup) {
		uint8_t warn_buf[48] = {0};
		strcpy((char*)warn_buf, "warning: ahrs startup did not converge");
		com_send(&com_conf, warn_buf, strlen((char*)warn_buf), 0);
		osDelay(10);
	}

	ori = FusionQuaternionToEuler(FusionAhrsGetQuaternion(&ahrs));

	for (i = 0; i < ITERATION; i++) {
		bmp388_read(&bmp388_data);
		altitude_offset += bmp388_data.altitude_m;
		HAL_Delay(200);
	}

	altitude_offset = altitude_offset / ITERATION;

	rx_integral = 0;
	ry_integral = 0;
	rz_integral = 0;
	pz_integral = 0;

	lpf_init(&lpf_altitude, 0.8f, 0.0f);
	lpf_init(&lpf_voltage, 0.1f, 11.1f);

	kalman_init(&kf_altitude, 3, 3, Q, R, x0); // kalman filter altitude init
	kalman_init(&kf_vel_x, 2, 2, Q_vel, R_vel, x0_vel);
	kalman_init(&kf_vel_y, 2, 2, Q_vel, R_vel, x0_vel);

	lqr_init(&lqr, 12, 4, K, u_min, u_max);
	lqr_set_ref(&lqr, x_ref);

	uint8_t buf[32] = {0};
	strcpy((char*)buf, "initialization complete");
	com_send(&com_conf, buf, strlen((char*)buf), 0);
}

void sys_check(void) {
	int i = 0;
	uint8_t com_buf[64];

	osMutexAcquire(spi1MutexHandle, osWaitForever);
	osMutexAcquire(spi2MutexHandle, osWaitForever);
	osMutexAcquire(i2c1MutexHandle, osWaitForever);

	osThreadSuspend(controlTaskHandle);

	osMutexRelease(i2c1MutexHandle);
	osMutexRelease(spi2MutexHandle);
	osMutexRelease(spi1MutexHandle);

	// init
	strncpy((char*)com_buf, "performing system check\n", sizeof(com_buf));
	com_send(&com_conf, com_buf, strlen((char*)com_buf), UTF_ENC);
	HAL_Delay(1000);

	// led & buzzer test
	strncpy((char*)com_buf, "led & buzzer check\n", sizeof(com_buf));
	com_send(&com_conf, com_buf, strlen((char*)com_buf), UTF_ENC);
	led_on();
	buzzer_play(melody, melody_len);

	// servo-x & servo-y test
	strncpy((char*)com_buf, "servo check\n", sizeof(com_buf));
	com_send(&com_conf, com_buf, strlen((char*)com_buf), UTF_ENC);
	servo_swipe(&servox_conf, 50, 100, 0, 2000);
	servo_swipe(&servoy_conf, 50, 100, 0, 2000);

	// motor1 & motor2 test
	strncpy((char*)com_buf, "motor check\n", sizeof(com_buf));
	com_send(&com_conf, com_buf, strlen((char*)com_buf), UTF_ENC);
	motor_swipe(&motor1_conf, 0, 10, 0, 1000);
	motor_swipe(&motor2_conf, 0, 10, 0, 1000);

	// test bmm150 magnetometer
	strncpy((char*)com_buf, "magnetometer check\n", sizeof(com_buf));
	com_send(&com_conf, com_buf, strlen((char*)com_buf), UTF_ENC);
	for (i = 0; i <=10; i++) {
		bmm150_read(&bmm150_data);
		HAL_Delay(100);
	}

	// test bmp388 barometer
	strncpy((char*)com_buf, "barometer check\n", sizeof(com_buf));
	com_send(&com_conf, com_buf, strlen((char*)com_buf), UTF_ENC);
	for (i = 0; i <=10; i++) {
		bmp388_read(&bmp388_data);
		HAL_Delay(100);
	}

	// test icm42688p inertial measurement unit
	strncpy((char*)com_buf, "inertial measurement unit check\n", sizeof(com_buf));
	com_send(&com_conf, com_buf, strlen((char*)com_buf), UTF_ENC);
	for (i = 0; i <=10; i++) {
		icm42688p_read(&icm42688p_data);
		HAL_Delay(100);
	}

	// test ina226 power sensor
	strncpy((char*)com_buf, "power check\n", sizeof(com_buf));
	com_send(&com_conf, com_buf, strlen((char*)com_buf), UTF_ENC);
	for (i = 0; i <=10; i++) {
		ina226_read(&ina226_data);
		HAL_Delay(100);
	}

	// test w25q128 flash
	strncpy((char*)com_buf, "flash check\n", sizeof(com_buf));
	com_send(&com_conf, com_buf, strlen((char*)com_buf), UTF_ENC);

	uint8_t write_buf[64];
	uint8_t read_buf[64] = {0};
	uint32_t test_addr = 0x000000;

	for(int j = 0; j < 64; j++) write_buf[j] = (uint8_t)(j);

	w25q128_erase(W25Q128_ERASE_SECTOR, test_addr);
	w25q128_wait_busy(W25Q128_TIMEOUT_SECTOR_ERASE_MS);
	w25q128_write(test_addr, write_buf, 64);
	w25q128_data_t read_data = { .buf = read_buf, .len = 64 };
	w25q128_read(test_addr, &read_data);
	HAL_Delay(1000);

	// test sdmmc
	strncpy((char*)com_buf, "sd card check\n", sizeof(com_buf));
	com_send(&com_conf, com_buf, strlen((char*)com_buf), UTF_ENC);

	char buffer[10];
	uint32_t bytes_written;
	res = f_mount(&fs, "", 1);
	res = f_open(&fil, "sys.csv", FA_WRITE | FA_CREATE_ALWAYS);
	for (int k = 0; k <= 63; k++) {
		int len = snprintf(buffer, sizeof(buffer), "%d\n", k);
		f_write(&fil, buffer, len, (UINT *)&bytes_written);
	}
	f_close(&fil);
	f_mount(NULL, "", 0);

	HAL_Delay(1000);
	strncpy((char*)com_buf, "system check complete\n", sizeof(com_buf));
	com_send(&com_conf, com_buf, strlen((char*)com_buf), UTF_ENC);

	HAL_Delay(1000);
	led_off();

	osMutexAcquire(stateMutexHandle, osWaitForever);
	dt_init = false;
	rz_unwrap_init = false;
	osMutexRelease(stateMutexHandle);
	osThreadResume(controlTaskHandle);
}
/* USER CODE END 0 */

int main(void)
{

  /* MPU Configuration--------------------------------------------------------*/
  MPU_Config();

  /* MCU Configuration--------------------------------------------------------*/

  /* Reset of all peripherals, Initializes the Flash interface and the Systick. */
  HAL_Init();

  /* Configure the system clock */
  SystemClock_Config();

  /* Initialize all configured peripherals */
  MX_GPIO_Init();
  MX_DMA_Init();
  MX_SDMMC1_SD_Init();
  MX_ADC1_Init();
  MX_I2C1_Init();
  MX_SPI1_Init();
  MX_SPI2_Init();
  MX_TIM2_Init();
  MX_TIM3_Init();
  MX_TIM4_Init();
  MX_USART3_UART_Init();
  MX_USART2_UART_Init();
  MX_TIM1_Init();
  MX_FATFS_Init();
  MX_TIM6_Init();

  /* Init scheduler */
  osKernelInitialize();  /* Call init function for freertos objects (in cmsis_os2.c) */
  MX_FREERTOS_Init();

  /* Start scheduler */
  osKernelStart();

  /* We should never get here as control is now taken by the scheduler */

  /* Infinite loop */
  while (1)
  {

  }
}

void SystemClock_Config(void)
{
  RCC_OscInitTypeDef RCC_OscInitStruct = {0};
  RCC_ClkInitTypeDef RCC_ClkInitStruct = {0};

  /** Configure the main internal regulator output voltage
  */
  __HAL_RCC_PWR_CLK_ENABLE();
  __HAL_PWR_VOLTAGESCALING_CONFIG(PWR_REGULATOR_VOLTAGE_SCALE1);

  /** Initializes the RCC Oscillators according to the specified parameters
  * in the RCC_OscInitTypeDef structure.
  */
  RCC_OscInitStruct.OscillatorType = RCC_OSCILLATORTYPE_HSE;
  RCC_OscInitStruct.HSEState = RCC_HSE_ON;
  RCC_OscInitStruct.PLL.PLLState = RCC_PLL_ON;
  RCC_OscInitStruct.PLL.PLLSource = RCC_PLLSOURCE_HSE;
  RCC_OscInitStruct.PLL.PLLM = 25;
  RCC_OscInitStruct.PLL.PLLN = 432;
  RCC_OscInitStruct.PLL.PLLP = RCC_PLLP_DIV2;
  RCC_OscInitStruct.PLL.PLLQ = 9;
  if (HAL_RCC_OscConfig(&RCC_OscInitStruct) != HAL_OK)
  {
    Error_Handler();
  }

  /** Activate the Over-Drive mode
  */
  if (HAL_PWREx_EnableOverDrive() != HAL_OK)
  {
    Error_Handler();
  }

  /** Initializes the CPU, AHB and APB buses clocks
  */
  RCC_ClkInitStruct.ClockType = RCC_CLOCKTYPE_HCLK|RCC_CLOCKTYPE_SYSCLK
                              |RCC_CLOCKTYPE_PCLK1|RCC_CLOCKTYPE_PCLK2;
  RCC_ClkInitStruct.SYSCLKSource = RCC_SYSCLKSOURCE_PLLCLK;
  RCC_ClkInitStruct.AHBCLKDivider = RCC_SYSCLK_DIV1;
  RCC_ClkInitStruct.APB1CLKDivider = RCC_HCLK_DIV4;
  RCC_ClkInitStruct.APB2CLKDivider = RCC_HCLK_DIV2;

  if (HAL_RCC_ClockConfig(&RCC_ClkInitStruct, FLASH_LATENCY_7) != HAL_OK)
  {
    Error_Handler();
  }
}

/* USER CODE BEGIN 4 */
void HAL_UART_RxCpltCallback(UART_HandleTypeDef *huart)
{
    if (huart->Instance == USART2) {
        com_rx_callback(&com_conf);
        osSemaphoreRelease(uart2RxSemHandle);
    }
}

void HAL_UART_ErrorCallback(UART_HandleTypeDef *huart)
{
    if (huart->Instance == USART2) {
        __HAL_UART_CLEAR_OREFLAG(huart);
        HAL_UART_Receive_IT(huart, (uint8_t *)&com_conf.rx_byte, 1);
    }
}

void icm_dma_complete_cb(HAL_StatusTypeDef status)
{
    osSemaphoreRelease(icmDmaSemHandle);
}

void pmw_dma_complete_cb(HAL_StatusTypeDef status)
{
    osSemaphoreRelease(pmwDmaSemHandle);
}

void bmm_dma_complete_cb(HAL_StatusTypeDef status)
{
    osSemaphoreRelease(bmmDmaSemHandle);
}

void bmp_dma_complete_cb(HAL_StatusTypeDef status)
{
    osSemaphoreRelease(bmpDmaSemHandle);
}

void ina_dma_complete_cb(HAL_StatusTypeDef status)
{
    osSemaphoreRelease(inaDmaSemHandle);
}

void flash_dma_complete_cb(HAL_StatusTypeDef status)
{
    osSemaphoreRelease(flashDmaSemHandle);
}

void HAL_UART_TxCpltCallback(UART_HandleTypeDef *huart)
{
    if (huart->Instance == USART2) {
        osSemaphoreRelease(uart2TxDmaSemHandle);
    }
}

void HAL_SPI_RxCpltCallback(SPI_HandleTypeDef *hspi)
{
    if (hspi->Instance == SPI2) {
		if (spi2_pending == SPI2_PENDING_ICM)      icm42688p_dma_irq_handler();
		else if (spi2_pending == SPI2_PENDING_PMW) pmw3901_dma_irq_handler();
		spi2_pending = SPI2_PENDING_NONE;
	} else if (hspi->Instance == SPI1) {
		bmp388_dma_irq_handler();
	}
}

void HAL_SPI_TxCpltCallback(SPI_HandleTypeDef *hspi)
{
    if (hspi->Instance == SPI1) {
        w25q128_dma_irq_handler();
    }
}

void HAL_I2C_MasterRxCpltCallback(I2C_HandleTypeDef *hi2c) {
    if (hi2c->Instance == I2C1) {
        if (i2c1_pending == I2C1_PENDING_BMM)       bmm150_dma_irq_handler();
        else if (i2c1_pending == I2C1_PENDING_VL53) osSemaphoreRelease(i2c1DmaSemHandle);
        i2c1_pending = I2C1_PENDING_NONE;
    }
}

void HAL_I2C_MasterTxCpltCallback(I2C_HandleTypeDef *hi2c) {
    if (hi2c->Instance == I2C1 && i2c1_pending == I2C1_PENDING_VL53) {
        osSemaphoreRelease(i2c1DmaSemHandle);
        i2c1_pending = I2C1_PENDING_NONE;
    }
}

void HAL_I2C_MemRxCpltCallback(I2C_HandleTypeDef *hi2c)
{
    if (hi2c->Instance == I2C1) {
        ina226_dma_irq_handler();
    }
}

/* USER CODE END 4 */

 /* MPU Configuration */

void MPU_Config(void)
{
  MPU_Region_InitTypeDef MPU_InitStruct = {0};

  /* Disables the MPU */
  HAL_MPU_Disable();

  /** Initializes and configures the Region and the memory to be protected
  */
  MPU_InitStruct.Enable = MPU_REGION_ENABLE;
  MPU_InitStruct.Number = MPU_REGION_NUMBER0;
  MPU_InitStruct.BaseAddress = 0x0;
  MPU_InitStruct.Size = MPU_REGION_SIZE_4GB;
  MPU_InitStruct.SubRegionDisable = 0x87;
  MPU_InitStruct.TypeExtField = MPU_TEX_LEVEL0;
  MPU_InitStruct.AccessPermission = MPU_REGION_NO_ACCESS;
  MPU_InitStruct.DisableExec = MPU_INSTRUCTION_ACCESS_DISABLE;
  MPU_InitStruct.IsShareable = MPU_ACCESS_SHAREABLE;
  MPU_InitStruct.IsCacheable = MPU_ACCESS_NOT_CACHEABLE;
  MPU_InitStruct.IsBufferable = MPU_ACCESS_NOT_BUFFERABLE;

  HAL_MPU_ConfigRegion(&MPU_InitStruct);
  /* Enables the MPU */
  HAL_MPU_Enable(MPU_PRIVILEGED_DEFAULT);

}

void HAL_TIM_PeriodElapsedCallback(TIM_HandleTypeDef *htim)
{
  if (htim->Instance == TIM7)
  {
    HAL_IncTick();
  }
  /* USER CODE BEGIN Callback 1 */
  if (htim->Instance == TIM6) { // 100Hz
	  static int div50 = 0, div10 = 0, div1 = 0;
	  uint32_t flags = CONTROL_100HZ_FLAG;

	  if (++div50 >= 2)   { flags |= CONTROL_50HZ_FLAG;   div50 = 0; } // 50Hz
	  if (++div10 >= 10)  { flags |= CONTROL_10HZ_FLAG;  div10 = 0; } // 10Hz
	  if (++div1  >= 100) { flags |= CONTROL_1HZ_FLAG; div1  = 0; } // 1Hz

	  osThreadFlagsSet(controlTaskHandle, flags);
  }
  /* USER CODE END Callback 1 */
}

void Error_Handler(void)
{
  __disable_irq();
  while (1)
  {
  }
}

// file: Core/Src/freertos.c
/* USER CODE BEGIN Header */
/**
  ******************************************************************************
  * File Name          : freertos.c
  * Description        : Code for freertos applications
  ******************************************************************************
  * @attention
  *
  * Copyright (c) 2026 STMicroelectronics.
  * All rights reserved.
  *
  * This software is licensed under terms that can be found in the LICENSE file
  * in the root directory of this software component.
  * If no LICENSE file comes with this software, it is provided AS-IS.
  *
  ******************************************************************************
  */
/* USER CODE END Header */

#include "FreeRTOS.h"
#include "task.h"
#include "main.h"
#include "cmsis_os.h"

/* USER CODE BEGIN Includes */
#include "global.h"

/* USER CODE END Includes */

/* Definitions for controlTask */
osThreadId_t controlTaskHandle;
const osThreadAttr_t controlTask_attributes = {
  .name = "controlTask",
  .stack_size = 2048 * 4,
  .priority = (osPriority_t) osPriorityRealtime,
};
/* Definitions for commandTask */
osThreadId_t commandTaskHandle;
const osThreadAttr_t commandTask_attributes = {
  .name = "commandTask",
  .stack_size = 512 * 4,
  .priority = (osPriority_t) osPriorityHigh,
};
/* Definitions for loggerTask */
osThreadId_t loggerTaskHandle;
const osThreadAttr_t loggerTask_attributes = {
  .name = "loggerTask",
  .stack_size = 256 * 4,
  .priority = (osPriority_t) osPriorityAboveNormal,
};
/* Definitions for telemetryTask */
osThreadId_t telemetryTaskHandle;
const osThreadAttr_t telemetryTask_attributes = {
  .name = "telemetryTask",
  .stack_size = 256 * 4,
  .priority = (osPriority_t) osPriorityNormal,
};
/* Definitions for transferTask */
osThreadId_t transferTaskHandle;
const osThreadAttr_t transferTask_attributes = {
  .name = "transferTask",
  .stack_size = 1024 * 4,
  .priority = (osPriority_t) osPriorityRealtime,
};
/* Definitions for loggerQueue */
osMessageQueueId_t loggerQueueHandle;
const osMessageQueueAttr_t loggerQueue_attributes = {
  .name = "loggerQueue"
};
/* Definitions for telemetryQueue */
osMessageQueueId_t telemetryQueueHandle;
const osMessageQueueAttr_t telemetryQueue_attributes = {
  .name = "telemetryQueue"
};
/* Definitions for transferQueue */
osMessageQueueId_t transferQueueHandle;
const osMessageQueueAttr_t transferQueue_attributes = {
  .name = "transferQueue"
};
/* Definitions for stateMutex */
osMutexId_t stateMutexHandle;
const osMutexAttr_t stateMutex_attributes = {
  .name = "stateMutex"
};
/* Definitions for spi1Mutex */
osMutexId_t spi1MutexHandle;
const osMutexAttr_t spi1Mutex_attributes = {
  .name = "spi1Mutex"
};
/* Definitions for comTxMutex */
osMutexId_t comTxMutexHandle;
const osMutexAttr_t comTxMutex_attributes = {
  .name = "comTxMutex"
};
/* Definitions for spi2Mutex */
osMutexId_t spi2MutexHandle;
const osMutexAttr_t spi2Mutex_attributes = {
  .name = "spi2Mutex"
};
/* Definitions for i2c1Mutex */
osMutexId_t i2c1MutexHandle;
const osMutexAttr_t i2c1Mutex_attributes = {
  .name = "i2c1Mutex"
};
/* Definitions for icmDmaSem */
osSemaphoreId_t icmDmaSemHandle;
const osSemaphoreAttr_t icmDmaSem_attributes = {
  .name = "icmDmaSem"
};
/* Definitions for bmpDmaSem */
osSemaphoreId_t bmpDmaSemHandle;
const osSemaphoreAttr_t bmpDmaSem_attributes = {
  .name = "bmpDmaSem"
};
/* Definitions for bmmDmaSem */
osSemaphoreId_t bmmDmaSemHandle;
const osSemaphoreAttr_t bmmDmaSem_attributes = {
  .name = "bmmDmaSem"
};
/* Definitions for inaDmaSem */
osSemaphoreId_t inaDmaSemHandle;
const osSemaphoreAttr_t inaDmaSem_attributes = {
  .name = "inaDmaSem"
};
/* Definitions for flashDmaSem */
osSemaphoreId_t flashDmaSemHandle;
const osSemaphoreAttr_t flashDmaSem_attributes = {
  .name = "flashDmaSem"
};
/* Definitions for uart2TxDmaSem */
osSemaphoreId_t uart2TxDmaSemHandle;
const osSemaphoreAttr_t uart2TxDmaSem_attributes = {
  .name = "uart2TxDmaSem"
};
/* Definitions for uart2RxSem */
osSemaphoreId_t uart2RxSemHandle;
const osSemaphoreAttr_t uart2RxSem_attributes = {
  .name = "uart2RxSem"
};
/* Definitions for pmwDmaSem */
osSemaphoreId_t pmwDmaSemHandle;
const osSemaphoreAttr_t pmwDmaSem_attributes = {
  .name = "pmwDmaSem"
};
/* Definitions for i2c1DmaSem */
osSemaphoreId_t i2c1DmaSemHandle;
const osSemaphoreAttr_t i2c1DmaSem_attributes = {
  .name = "i2c1DmaSem"
};

void ControlTask(void *argument);
void CommandTask(void *argument);
void LoggerTask(void *argument);
void TelemetryTask(void *argument);
void TransferTask(void *argument);

extern void MX_USB_DEVICE_Init(void);
void MX_FREERTOS_Init(void); /* (MISRA C 2004 rule 8.1) */

// Set by CMD_LAND in CommandTask, read every cycle in ControlTask. Kept as a
// plain file-scope flag (not routed through global.h) since both tasks that
// touch it live in this file — writes go through stateMutexHandle to match
// the existing convention for cross-task flags like dt_init/rz_unwrap_init.
static volatile bool landing_active = false;

#define LAND_DESCENT_RATE_MPS   0.4f
#define LAND_ALT_THRESHOLD_M    0.10f
#define LAND_THRUST_THRESHOLD   2.6f

void MX_FREERTOS_Init(void) {
  /* Create the mutex(es) */
  /* creation of stateMutex */
  stateMutexHandle = osMutexNew(&stateMutex_attributes);

  /* creation of spi1Mutex */
  spi1MutexHandle = osMutexNew(&spi1Mutex_attributes);

  /* creation of comTxMutex */
  comTxMutexHandle = osMutexNew(&comTxMutex_attributes);

  /* creation of spi2Mutex */
  spi2MutexHandle = osMutexNew(&spi2Mutex_attributes);

  /* creation of i2c1Mutex */
  i2c1MutexHandle = osMutexNew(&i2c1Mutex_attributes);

  /* Create the semaphores(s) */
  /* creation of icmDmaSem */
  icmDmaSemHandle = osSemaphoreNew(1, 0, &icmDmaSem_attributes);

  /* creation of bmpDmaSem */
  bmpDmaSemHandle = osSemaphoreNew(1, 0, &bmpDmaSem_attributes);

  /* creation of bmmDmaSem */
  bmmDmaSemHandle = osSemaphoreNew(1, 0, &bmmDmaSem_attributes);

  /* creation of inaDmaSem */
  inaDmaSemHandle = osSemaphoreNew(1, 0, &inaDmaSem_attributes);

  /* creation of flashDmaSem */
  flashDmaSemHandle = osSemaphoreNew(1, 0, &flashDmaSem_attributes);

  /* creation of uart2TxDmaSem */
  uart2TxDmaSemHandle = osSemaphoreNew(1, 0, &uart2TxDmaSem_attributes);

  /* creation of uart2RxSem */
  uart2RxSemHandle = osSemaphoreNew(1, 0, &uart2RxSem_attributes);

  /* creation of pmwDmaSem */
  pmwDmaSemHandle = osSemaphoreNew(1, 0, &pmwDmaSem_attributes);

  /* creation of i2c1DmaSem */
  i2c1DmaSemHandle = osSemaphoreNew(1, 0, &i2c1DmaSem_attributes);

  /* Create the queue(s) */
  /* creation of loggerQueue */
  loggerQueueHandle = osMessageQueueNew (16, sizeof(flight_log_t), &loggerQueue_attributes);

  /* creation of telemetryQueue */
  telemetryQueueHandle = osMessageQueueNew (4, sizeof(telemetry_packet_t), &telemetryQueue_attributes);

  /* creation of transferQueue */
  transferQueueHandle = osMessageQueueNew (1, sizeof(uint8_t), &transferQueue_attributes);

  /* Create the thread(s) */
  /* creation of controlTask */
  controlTaskHandle = osThreadNew(ControlTask, NULL, &controlTask_attributes);

  /* creation of commandTask */
  commandTaskHandle = osThreadNew(CommandTask, NULL, &commandTask_attributes);

  /* creation of loggerTask */
  loggerTaskHandle = osThreadNew(LoggerTask, NULL, &loggerTask_attributes);

  /* creation of telemetryTask */
  telemetryTaskHandle = osThreadNew(TelemetryTask, NULL, &telemetryTask_attributes);

  /* creation of transferTask */
  transferTaskHandle = osThreadNew(TransferTask, NULL, &transferTask_attributes);

}

void ControlTask(void *argument)
{
  /* init code for USB_DEVICE */
  MX_USB_DEVICE_Init();
  /* USER CODE BEGIN ControlTask */
  sys_init();
//  motor_calibrate_escs(&motor1_conf, &motor2_conf);
  HAL_TIM_Base_Start_IT(&htim6);
  static uint32_t pv_tick_ms = 0;
  static float delta_time;
  static float tof_altitude_m = 0.0f;
  static bool prev_sat_rx = true;
  static bool prev_sat_ry = true;
  static bool prev_sat_velx = true;
  static bool prev_sat_vely = true;
  static float prev_thrust = HOVER_THRUST;
  static float baro_tof_offset = 0.0f;
  static float land_ref_z = 0.0f;
  static bool land_ramp_init = false;
  /* Infinite loop */
  for(;;)
		{
		  uint32_t flags = osThreadFlagsWait(CONTROL_ALL_FLAGS, osFlagsWaitAny, osWaitForever);

		  if ((flags & 0x80000000) != 0) {
			  continue;
		  }

		  bool flag_50hz = (flags & CONTROL_50HZ_FLAG) != 0;
		  bool flag_10hz = (flags & CONTROL_10HZ_FLAG) != 0;
		  bool flag_1hz  = (flags & CONTROL_1HZ_FLAG)  != 0;

		  if (!dt_init) {
			  delta_time = DEFAULT_DT;
			  pv_tick_ms = HAL_GetTick();
			  prev_thrust = HOVER_THRUST;
			  prev_sat_rx = true;
			  prev_sat_ry = true;
			  prev_sat_velx = true;
			  prev_sat_vely = true;
			  tof_altitude_m = 0.0f;
			  baro_tof_offset = altitude_offset;
			  osMutexAcquire(stateMutexHandle, osWaitForever);
			  dt_init = true;
			  osMutexRelease(stateMutexHandle);
		  } else {
			  uint32_t now_ms = HAL_GetTick();
			  delta_time = (float)(now_ms - pv_tick_ms) * 0.001f; // convert to seconds
			  pv_tick_ms = now_ms;
		  }

		  float local_x_ref[12];
		  drone_state_t local_state;
		  int local_servox_offset, local_servoy_offset;
		  osMutexAcquire(stateMutexHandle, osWaitForever);
		  memcpy(local_x_ref, x_ref, sizeof(local_x_ref));
		  local_state = drone_state;
		  local_servox_offset = servox_conf.offset;
		  local_servoy_offset = servoy_conf.offset;
		  osMutexRelease(stateMutexHandle);

	  osMutexAcquire(spi2MutexHandle, osWaitForever);
	  spi2_pending = SPI2_PENDING_ICM;
	  icm42688p_read_dma(&icm42688p_data, icm_dma_complete_cb);
	  osMutexRelease(spi2MutexHandle);
	  if (osSemaphoreAcquire(icmDmaSemHandle, SENSOR_DMA_TIMEOUT_MS) == osOK) {
		  gyro  = (FusionVector) {{icm42688p_data.gyro_x_dps,  icm42688p_data.gyro_y_dps,  icm42688p_data.gyro_z_dps}};
		  accel = (FusionVector) {{icm42688p_data.accel_x_g,   icm42688p_data.accel_y_g,   icm42688p_data.accel_z_g}};
		  gyro  = FusionModelInertial(gyro,  gyro_misalignment,  gyro_sensitivity,  gyro_offset);
		  accel = FusionModelInertial(accel, accel_misalignement, accel_sensitivity, accel_offset);
		  gyro  = FusionBiasUpdate(&bias, gyro);
	  }

	  float flow_dx = 0.0f, flow_dy = 0.0f;
	  osMutexAcquire(spi2MutexHandle, osWaitForever);
	  spi2_pending = SPI2_PENDING_PMW;
	  pmw3901_read_dma(&pmw3901_data, pmw_dma_complete_cb);
	  osMutexRelease(spi2MutexHandle);
	  if (osSemaphoreAcquire(pmwDmaSemHandle, SENSOR_DMA_TIMEOUT_MS) == osOK) {
		  const float PMW_MOUNT_COS45 = 0.70710678f;
		  const float PMW_MOUNT_SIN45 = 0.70710678f;
		  float raw_dx = (float)pmw3901_data.delta_x;
		  float raw_dy = (float)pmw3901_data.delta_y;
		  flow_dx = raw_dx * PMW_MOUNT_COS45 - raw_dy * PMW_MOUNT_SIN45;
		  flow_dy = raw_dx * PMW_MOUNT_SIN45 + raw_dy * PMW_MOUNT_COS45;
	  }

	  osMutexAcquire(i2c1MutexHandle, osWaitForever);
	  ina226_read_dma(&ina226_data, ina_dma_complete_cb);
	  osSemaphoreAcquire(inaDmaSemHandle, SENSOR_DMA_TIMEOUT_MS);
	  osMutexRelease(i2c1MutexHandle);
	  float voltage = lpf_update(&lpf_voltage, ina226_data.bus_voltage_V);

	  if (flag_10hz) {
		  osMutexAcquire(i2c1MutexHandle, osWaitForever);
		  i2c1_pending = I2C1_PENDING_BMM;
		  bmm150_read_dma(&bmm150_data, bmm_dma_complete_cb);
		  bool bmm_ok = (osSemaphoreAcquire(bmmDmaSemHandle, SENSOR_DMA_TIMEOUT_MS) == osOK); // FIX: was unchecked
		  osMutexRelease(i2c1MutexHandle);

		  if (bmm_ok) {
			  mag = (FusionVector) {{bmm150_data.mag_x_uT, bmm150_data.mag_y_uT, bmm150_data.mag_z_uT}};
			  mag = FusionModelMagnetic(mag, mag_softIronMatrix, mag_hardIronOffset);
			  FusionAhrsUpdate(&ahrs, gyro, accel, mag, delta_time);
		  } else {
			  FusionAhrsUpdateNoMagnetometer(&ahrs, gyro, accel, delta_time);
		  }
	  } else {
		  FusionAhrsUpdateNoMagnetometer(&ahrs, gyro, accel, delta_time);
	  }

	  ori = FusionQuaternionToEuler(FusionAhrsGetQuaternion(&ahrs));
	  lin_accel = FusionAhrsGetLinearAcceleration(&ahrs);

	  float rx = DEG_TO_RAD(ori.angle.roll);
	  float ry = DEG_TO_RAD(ori.angle.pitch);

	  bool  tof_valid = false;
	  if (flag_10hz) {
		  osMutexAcquire(i2c1MutexHandle, osWaitForever);
		  uint8_t vlx_ready = 0;
		  VL53L1X_CheckForDataReady(vl53l1x_dev, &vlx_ready);
		  if (vlx_ready) {
		      uint16_t vlx_distance_mm = 0;
		      uint8_t  vlx_status = 0;

		      VL53L1X_GetDistance(vl53l1x_dev, &vlx_distance_mm);
		      VL53L1X_GetRangeStatus(vl53l1x_dev, &vlx_status);
		      VL53L1X_ClearInterrupt(vl53l1x_dev);   // Required every read or the sensor stalls

		      if (vlx_status == 0) {
		          float candidate = (vlx_distance_mm / 1000.0f) * cosf(rx) * cosf(ry);
		          if (candidate > 0.04f && candidate < 4.0f) { // sensor ranges from 4cm to 4m
		              tof_altitude_m = candidate;
		              tof_valid = true;
		          } else {
		              tof_valid = false;
		          }
		      } else {
		          tof_valid = false;
		      }
		  }
		  osMutexRelease(i2c1MutexHandle);
	  }

	  float F[KALMAN_MAX_DIM][KALMAN_MAX_DIM] = {
		  {1,          0,  0},
		  {delta_time,         1,  0},
		  {0.5f*delta_time*delta_time, delta_time, 1}
	  };
	  kalman_predict(&kf_altitude, F, NULL, NULL, delta_time);

	  float H[KALMAN_MAX_MEAS][KALMAN_MAX_DIM] = {0};
	  float z[KALMAN_MAX_MEAS] = {0};
	  H[0][0] = 1.0f;
	  z[0] = -lin_accel.axis.z * 9.81f;

	  bool  bmp_ok = false;
	  float baro_filtered = 0.0f;

	  if (flag_50hz) {
		  osMutexAcquire(spi1MutexHandle, osWaitForever);
		  bmp388_read_dma(&bmp388_data, bmp_dma_complete_cb);
		  bmp_ok = (osSemaphoreAcquire(bmpDmaSemHandle, SENSOR_DMA_TIMEOUT_MS) == osOK); // FIX: was unchecked
		  osMutexRelease(spi1MutexHandle);

		  if (bmp_ok) {
			  baro_filtered = lpf_update(&lpf_altitude, bmp388_data.altitude_m);
		  }
	  }

	  if (tof_valid) {
		  // TOF is the authoritative altitude source in range — use it alone
		  // rather than fusing it alongside the noisier barometer, and keep
		  // recalibrating the barometer's offset against it so the fallback
		  // below picks up from the right point instead of an ARM-time value
		  // that's since drifted.
		  H[2][2] = 1.0f;
		  z[2] = tof_altitude_m;

		  if (bmp_ok) {
			  baro_tof_offset = baro_filtered - tof_altitude_m;
		  }
	  } else if (bmp_ok) {
		  H[1][2] = 1.0f;
		  z[1] = baro_filtered - baro_tof_offset;
	  }

	  kalman_update(&kf_altitude, H, z);
	  vel.axis.z = kalman_get_state(&kf_altitude, 1);
	  pos.axis.z = kalman_get_state(&kf_altitude, 2);

	  float pz = pos.axis.z;

	  const float PMW_RAD_PER_COUNT = 0.0023529f;
	  float flow_height_m = pos.axis.z;
	  const uint8_t PMW_SQUAL_MIN = 25; // surface quality minimum
	  float vx_raw = 0.0f, vy_raw = 0.0f;
	  bool  flow_valid = (pmw3901_data.squal >= PMW_SQUAL_MIN) && (flow_height_m > 0.05f) && (delta_time > 0.0f);

	  float rz_wrapped = DEG_TO_RAD(ori.angle.yaw);

	  if (!rz_unwrap_init) {
		  osMutexAcquire(stateMutexHandle, osWaitForever);
		  rz_offset = rz_wrapped;
		  rz_unwrapped = rz_wrapped;
		  rz_prev_wrapped = rz_wrapped;
		  rz_unwrap_init = true;
		  osMutexRelease(stateMutexHandle);
	  } else {
		  float delta = rz_wrapped - rz_prev_wrapped;
		  if (delta > (float)M_PI)       delta -= 2.0f * (float)M_PI; // wrapping boundary is PI/0.001 radians per second
		  else if (delta < -(float)M_PI) delta += 2.0f * (float)M_PI;
		  osMutexAcquire(stateMutexHandle, osWaitForever);
		  rz_unwrapped += delta;
		  rz_prev_wrapped = rz_wrapped;
		  osMutexRelease(stateMutexHandle);
	  }
	  float rz = rz_unwrapped - rz_offset;

	  float Fx[KALMAN_MAX_DIM][KALMAN_MAX_DIM] = {
		  {1,          0},
		  {delta_time, 1}
	  };
	  kalman_predict(&kf_vel_x, Fx, NULL, NULL, delta_time);

	  float Fy[KALMAN_MAX_DIM][KALMAN_MAX_DIM] = {
		  {1,          0},
		  {delta_time, 1}
	  };
	  kalman_predict(&kf_vel_y, Fy, NULL, NULL, delta_time);

	  float Hx[KALMAN_MAX_MEAS][KALMAN_MAX_DIM] = {0};
	  float zx[KALMAN_MAX_MEAS] = {0};
	  Hx[0][0] = 1.0f;

	  float Hy[KALMAN_MAX_MEAS][KALMAN_MAX_DIM] = {0};
	  float zy[KALMAN_MAX_MEAS] = {0};
	  Hy[0][0] = 1.0f;

	  float world_accel_x = lin_accel.axis.x * cosf(ry) - lin_accel.axis.z * sinf(ry);
	  float world_accel_y = lin_accel.axis.y * cosf(rx) + lin_accel.axis.z * sinf(rx);
	  zx[0] = -world_accel_x * 9.81f;
	  zy[0] = -world_accel_y * 9.81f;

	  if (flow_valid) {
		  float gyro_rad_x = DEG_TO_RAD(gyro.axis.x);
		  float gyro_rad_y = DEG_TO_RAD(gyro.axis.y);
		  float omega_x = (flow_dx * PMW_RAD_PER_COUNT) / delta_time - gyro_rad_y;
		  float omega_y = (flow_dy * PMW_RAD_PER_COUNT) / delta_time + gyro_rad_x;

		  vx_raw = omega_x * flow_height_m;
		  vy_raw = omega_y * flow_height_m;

		  Hx[1][1] = 1.0f;
		  zx[1] = vx_raw;

		  Hy[1][1] = 1.0f;
		  zy[1] = vy_raw;
	  }

	  kalman_update(&kf_vel_x, Hx, zx);
	  kalman_update(&kf_vel_y, Hy, zy);

	  vel.axis.x = kalman_get_state(&kf_vel_x, 1);
	  vel.axis.y = kalman_get_state(&kf_vel_y, 1);
//	  vel.axis.x = vx_raw;
//	  vel.axis.y = vy_raw;

	  if (flow_valid) {
		  float cos_yaw = cosf(rz);
		  float sin_yaw = sinf(rz);
		  float vel_world_x = vel.axis.x * cos_yaw - vel.axis.y * sin_yaw;
		  float vel_world_y = vel.axis.x * sin_yaw + vel.axis.y * cos_yaw;

		  pos.axis.x += delta_time * vel_world_x;
		  pos.axis.y += delta_time * vel_world_y;
	  }
	  osMutexAcquire(stateMutexHandle, osWaitForever);

	  float vx_px_ctrl = 0.0f;
	  float vy_py_ctrl = 0.0f;
	  float rx_vy_ctrl = 0.0f;
	  float ry_vx_ctrl = 0.0f;

	  if (local_state == DRONE_FLYING) {
		  bool hold_integral_x = !prev_sat_ry || !prev_sat_velx;
		  bool hold_integral_y = !prev_sat_rx || !prev_sat_vely;
		  if (pos.axis.z <= 0.3) {
			  vx_px_ctrl = pid_update(&pos_p_x, cmd_ref[0], pos.axis.x, delta_time, hold_integral_x);
			  vy_py_ctrl = pid_update(&pos_p_y, cmd_ref[1], pos.axis.y, delta_time, hold_integral_y);
			  ry_vx_ctrl = pid_update(&vel_pid_x, vx_px_ctrl, vel.axis.x, delta_time, hold_integral_x)
						   * NOMINAL_THRUST / fmaxf(prev_thrust, THRUST_LCLAMP);
			  rx_vy_ctrl = pid_update(&vel_pid_y, vy_py_ctrl, vel.axis.y, delta_time, hold_integral_y)
						   * NOMINAL_THRUST / fmaxf(prev_thrust, THRUST_LCLAMP);

			  bool not_sat_velx = (vel_pid_x.output_held > vel_pid_x.output_min * 0.99f) &&
								   (vel_pid_x.output_held < vel_pid_x.output_max * 0.99f);
			  bool not_sat_vely = (vel_pid_y.output_held > vel_pid_y.output_min * 0.99f) &&
								   (vel_pid_y.output_held < vel_pid_y.output_max * 0.99f);
			  prev_sat_velx = not_sat_velx;
			  prev_sat_vely = not_sat_vely;
		  } else {
			  ry_vx_ctrl = pid_update(&vel_pid_x, vx_px_ctrl, vel.axis.x, delta_time, hold_integral_x)
			  						   * NOMINAL_THRUST / fmaxf(prev_thrust, THRUST_LCLAMP);
			  rx_vy_ctrl = pid_update(&vel_pid_y, vy_py_ctrl, vel.axis.y, delta_time, hold_integral_y)
						   * NOMINAL_THRUST / fmaxf(prev_thrust, THRUST_LCLAMP);

			  ry_vx_ctrl = ry_vx_ctrl*0.1;
			  rx_vy_ctrl = rx_vy_ctrl*0.1;
		  }
	  } else {
		  pid_reset(&pos_p_x);
		  pid_reset(&pos_p_y);
		  pid_reset(&vel_pid_x);
		  pid_reset(&vel_pid_y);
	  }

	  x_ref[0] = rx_vy_ctrl + DEG_TO_RAD(ref_rx_offset);
	  x_ref[1] = ry_vx_ctrl + DEG_TO_RAD(ref_ry_offset);
	  x_ref[2] = DEG_TO_RAD(ref_rz_offset);

	  if (landing_active) {
		  if (!land_ramp_init) {
			  land_ref_z = pz;
			  land_ramp_init = true;
		  }
		  if ((pos.axis.x*pos.axis.x + pos.axis.y*pos.axis.y) < 0.2) {
			  land_ref_z -= LAND_DESCENT_RATE_MPS * delta_time;
			  x_ref[3] = land_ref_z;

		  }
	  } else {
		  land_ramp_init = false;
		  x_ref[3] = cmd_ref[2] + ref_pz_offset;
	  }

	  lqr_set_ref(&lqr, x_ref);
	  memcpy(local_x_ref, x_ref, sizeof(local_x_ref));
	  osMutexRelease(stateMutexHandle);

	  float erx = rx - local_x_ref[0];
	  float ery = ry - local_x_ref[1];
	  float erz = rz - local_x_ref[2];
	  float epz = pz - local_x_ref[3];

	  if (local_state == DRONE_ARMED) {
		  if (flag_50hz) {
			  servo_set(&servox_conf, LQR_SSO);
			  servo_set(&servoy_conf, LQR_SSO);
		  }
		  motor_set(&motor1_conf, 0.0f);
		  motor_set(&motor2_conf, 0.0f);

		  rx_integral = 0; ry_integral = 0; rz_integral = 0; pz_integral = 0;
		  prev_thrust = HOVER_THRUST;
	  } else if (local_state == DRONE_FLYING) {
		  float x_state[] = {
			  rx, ry, rz, pz,
			  DEG_TO_RAD(gyro.axis.x), DEG_TO_RAD(gyro.axis.y), DEG_TO_RAD(gyro.axis.z),
			  vel.axis.z,
			  rx_integral, ry_integral, rz_integral, pz_integral,
		  };

		  lqr_compute(&lqr, x_state);

		  float thrust = HOVER_THRUST + lqr.u[3];
		  float clamped_thrust = fmaxf(thrust, THRUST_LCLAMP);

		  float motor1_cmd = 0;
		  float motor2_cmd = 0;
		  bool near_ground = landing_active && (pz < LAND_ALT_THRESHOLD_M);

		  float servo_x_cmd, servo_y_cmd;
		  if (near_ground) {
			  servo_x_cmd = LQR_SSO;
			  servo_y_cmd = LQR_SSO;
			  motor1_cmd = 0;
			  motor2_cmd = 0;

		  } else {
			  if (thrust > 0.0f) {
				  motor1_cmd = THRUST_TO_PWM(voltage, (thrust / G + lqr.u[2] / 2));
				  motor2_cmd = THRUST_TO_PWM(voltage, (thrust / G - lqr.u[2] / 2));
			  }
			  servo_x_cmd = LQR_SXSS * lqr.u[0] * NOMINAL_THRUST / clamped_thrust + LQR_SSO;
			  servo_y_cmd = LQR_SSO - (LQR_SYSS * lqr.u[1] * NOMINAL_THRUST / clamped_thrust);
		  }

		  if (motor1_cmd <   0.0f) motor1_cmd =   0.0f;
		  if (motor1_cmd > 100.0f) motor1_cmd = 100.0f;
		  if (motor2_cmd <   0.0f) motor2_cmd =   0.0f;
		  if (motor2_cmd > 100.0f) motor2_cmd = 100.0f;

		  motor_set(&motor1_conf, motor1_cmd);
		  motor_set(&motor2_conf, motor2_cmd);

		  servo_set(&servox_conf, servo_x_cmd);
		  servo_set(&servoy_conf, servo_y_cmd);

		  float sat_rx = (lqr.u[0] > u_min[0] * 0.99f) && (lqr.u[0] < u_max[0] * 0.99f);
		  float sat_ry = (lqr.u[1] > u_min[1] * 0.99f) && (lqr.u[1] < u_max[1] * 0.99f);
		  float sat_rz = (lqr.u[2] > u_min[2] * 0.99f) && (lqr.u[2] < u_max[2] * 0.99f);
		  float sat_pz = (lqr.u[3] > u_min[3] * 0.99f) && (lqr.u[3] < u_max[3] * 0.99f);

		  prev_sat_rx = sat_rx;
		  prev_sat_ry = sat_ry;
		  prev_thrust = thrust;

		  if (sat_rx) rx_integral += erx * delta_time;
		  if (sat_ry) ry_integral += ery * delta_time;
		  if (sat_rz) rz_integral += erz * delta_time;
		  if (sat_pz) pz_integral += epz * delta_time;

		  if (rx_integral >  RX_INTEGRAL_MAX) rx_integral =  RX_INTEGRAL_MAX;
		  if (rx_integral < -RX_INTEGRAL_MAX) rx_integral = -RX_INTEGRAL_MAX;
		  if (ry_integral >  RY_INTEGRAL_MAX) ry_integral =  RY_INTEGRAL_MAX;
		  if (ry_integral < -RY_INTEGRAL_MAX) ry_integral = -RY_INTEGRAL_MAX;
		  if (rz_integral >  RZ_INTEGRAL_MAX) rz_integral =  RZ_INTEGRAL_MAX;
		  if (rz_integral < -RZ_INTEGRAL_MAX) rz_integral = -RZ_INTEGRAL_MAX;
		  if (pz_integral >  PZ_INTEGRAL_MAX) pz_integral =  PZ_INTEGRAL_MAX;
		  if (pz_integral < -PZ_INTEGRAL_MAX) pz_integral = -PZ_INTEGRAL_MAX;

		  if (landing_active) {
				  bool thrust_low = (thrust < LAND_THRUST_THRESHOLD);

				  if (near_ground && thrust_low) {
					  motor_set(&motor1_conf, 0.0f);
					  motor_set(&motor2_conf, 0.0f);
					  servo_set(&servox_conf, LQR_SSO);
					  servo_set(&servoy_conf, LQR_SSO);

					  osMutexAcquire(stateMutexHandle, osWaitForever);
					  drone_state = DRONE_DISARMED;
					  landing_active = false;
					  osMutexRelease(stateMutexHandle);

					  land_ramp_init = false;
					  rx_integral = 0; ry_integral = 0; rz_integral = 0; pz_integral = 0;

					  uint8_t land_msg[16];
					  strcpy((char*)land_msg, "LANDED");
					  com_send(&com_conf, land_msg, strlen((char*)land_msg), 0);
				  }
		  }

		  flight_log_t current_log = {
			  .timestamp_ms = HAL_GetTick(),
			  .drone_state  = (uint8_t) local_state,
			  .accel = accel,
			  .gyro  = gyro,
			  .mag   = mag,
			  .baro_altitude_m = bmp388_data.altitude_m - altitude_offset,
			  .tof_altitude_m  = tof_altitude_m,
			  .flow_dx = flow_dx,
			  .flow_dy = flow_dy,
			  .voltage = voltage,
			  .rx = rx, .ry = ry, .rz = rz,
			  .pos_x = pos.axis.x, .pos_y = pos.axis.y, .pos_z = pos.axis.z,
			  .pos_p_out_x = vx_px_ctrl, .pos_p_out_y = vy_py_ctrl,
			  .vel_pid_out_x = ry_vx_ctrl, .vel_pid_out_y = rx_vy_ctrl,
			  .lqr_u = { lqr.u[0], lqr.u[1], lqr.u[2], lqr.u[3] },
			  .servo_x = servo_x_cmd,
			  .servo_y = servo_y_cmd,
			  .motor1  = motor1_cmd,
			  .motor2  = motor2_cmd,
		  };

		  osMessageQueuePut(loggerQueueHandle, &current_log, 0, 0);
	  } else {
		  motor_set(&motor1_conf, 0);
		  motor_set(&motor2_conf, 0);
		  prev_sat_rx = true;
		  prev_sat_ry = true;
	  }

	  if (flag_1hz) {
		  led_toggle();
		  telemetry_packet_t pkt = {
			  .accel = accel, .gyro = gyro, .mag = mag,
			  .flow_dx = flow_dx, .flow_dy = flow_dy,
			  .baro_altitude_m = bmp388_data.altitude_m - altitude_offset,
			  .tof_altitude_m  = tof_altitude_m,
			  .bus_voltage_V   = ina226_data.bus_voltage_V,
			  .pos = pos, .ori = ori,
		  };
		  osMessageQueuePut(telemetryQueueHandle, &pkt, 0, 0);
	  }
	}
  /* USER CODE END ControlTask */
}

void CommandTask(void *argument)
{
  /* USER CODE BEGIN CommandTask */
	/* Infinite loop */
	for(;;)
	{
	com_cmd_t cmd = {0};
	uint8_t msg[64];
	osSemaphoreAcquire(uart2RxSemHandle, osWaitForever);

	if (!com_rx_parse_utf8(&com_conf, &cmd)) {
		continue;
	} else {
		switch (cmd.type) {
			  case CMD_CHECK: {
				  strcpy((char*)msg, "CHECK");
				  com_send(&com_conf, msg, strlen((char*)msg), 0);
				  osDelay(10);
				  sys_check();

				  osMutexAcquire(stateMutexHandle, osWaitForever);
				  drone_state = DRONE_INIT;
				  osMutexRelease(stateMutexHandle);
				  break;
			  }

			  case CMD_STATUS: {
				  osMutexAcquire(stateMutexHandle, osWaitForever);
				  int len = snprintf((char*)msg, sizeof(msg), "STATUS x_ref: rx=%.3f ry=%.3f rz=%.3f pz=%.3f\n", x_ref[0], x_ref[1], x_ref[2], x_ref[3]);
				  osMutexRelease(stateMutexHandle);
				  com_send(&com_conf, msg, len, UTF_ENC);
				  osDelay(10);
				  break;
			  }

			  case CMD_ARM: {
			      strcpy((char*)msg, "ARM");
			      com_send(&com_conf, msg, strlen((char*)msg), 0);
			      osDelay(10);
			      strncpy((char*)msg, "clearing flash logs...\n", sizeof(msg));
			      com_send(&com_conf, msg, strlen((char*)msg), UTF_ENC);
			      osMutexAcquire(spi1MutexHandle, osWaitForever);
			      osMutexAcquire(spi2MutexHandle, osWaitForever);
			      osMutexAcquire(i2c1MutexHandle, osWaitForever);

			      osThreadSuspend(controlTaskHandle);

			      for (uint32_t addr = 0; addr < 0x100000; addr += 4096) {
			          w25q128_erase(W25Q128_ERASE_SECTOR, addr);
			          w25q128_wait_busy(W25Q128_TIMEOUT_SECTOR_ERASE_MS);
			      }

			      int ITERATION = 30;
			      float altitude_sum = 0;
			      for (int i = 0; i < ITERATION; i++) {
					bmp388_read(&bmp388_data);
					altitude_sum += bmp388_data.altitude_m;
					HAL_Delay(200);
			      }

			      osMutexAcquire(stateMutexHandle, osWaitForever);
			      x_ref[0] = DEG_TO_RAD(ref_rx_offset);
				  x_ref[1] = DEG_TO_RAD(ref_ry_offset);
				  x_ref[2] = DEG_TO_RAD(ref_rz_offset);
				  x_ref[3] = ref_pz_offset;
				  pos.axis.x = 0;
				  pos.axis.y = 0;
				  altitude_offset = altitude_sum / ITERATION;
				  lqr_set_ref(&lqr, x_ref);
				  pid_reset(&vel_pid_x);
				  pid_reset(&vel_pid_y);
				  rz_unwrap_init = false;
				  dt_init = false;

				  VL53L1X_SensorInit(vl53l1x_dev);
				  VL53L1X_SetDistanceMode(vl53l1x_dev, 1); // distance mode 1:short, 2:long
				  VL53L1X_SetTimingBudgetInMs(vl53l1x_dev, 20);
				  VL53L1X_SetInterMeasurementInMs(vl53l1x_dev, 20);
				  VL53L1X_StartRanging(vl53l1x_dev);

				  kalman_init(&kf_altitude, 3, 3, Q, R, x0);
				  kalman_init(&kf_vel_x, 2, 2, Q_vel, R_vel, x0_vel);
				  kalman_init(&kf_vel_y, 2, 2, Q_vel, R_vel, x0_vel);

				  drone_state = DRONE_ARMED;

				  osMutexRelease(stateMutexHandle);

			      osThreadResume(controlTaskHandle);

			      osMutexRelease(i2c1MutexHandle);
			      osMutexRelease(spi2MutexHandle);
			      osMutexRelease(spi1MutexHandle);

			      flash_write_address = 0x000000;
			      flash_buf_idx = 0;

			      strcpy((char*)msg, "armed!");
			      com_send(&com_conf, msg, strlen((char*)msg), 0);
			      break;
			  }

			  case CMD_LAUNCH: {
				  strcpy((char*)msg, "LAUNCH");
				  com_send(&com_conf, msg, strlen((char*)msg), 0);

				  osMutexAcquire(stateMutexHandle, osWaitForever);
				  pid_reset(&vel_pid_x);
				  pid_reset(&vel_pid_y);
				  if (drone_state == DRONE_ARMED) drone_state = DRONE_FLYING;
				  osMutexRelease(stateMutexHandle);
				  break;
			  }

			  case CMD_LAND: {
				  strcpy((char*)msg, "LAND");
				  com_send(&com_conf, msg, strlen((char*)msg), 0);

				  osMutexAcquire(stateMutexHandle, osWaitForever);
				  if (drone_state == DRONE_FLYING) {
					  landing_active = true;
				  }
				  osMutexRelease(stateMutexHandle);
				  break;
			  }

			  case CMD_KILL: {
			      osThreadSuspend(controlTaskHandle);
			      osThreadSuspend(loggerTaskHandle);
			      osThreadSuspend(telemetryTaskHandle);
			      osThreadSuspend(transferTaskHandle);

			      motor_set(&motor1_conf, 0);
			      motor_set(&motor2_conf, 0);
			      servo_set(&servox_conf, LQR_SSO);
			      servo_set(&servoy_conf, LQR_SSO);

			      strcpy((char*)msg, "KILL");
			      com_send(&com_conf, msg, strlen((char*)msg), 0);
			      osDelay(10);

			      osMutexAcquire(stateMutexHandle, osWaitForever);
			      drone_state = DRONE_DISARMED;
			      landing_active = false;
			      osMutexRelease(stateMutexHandle);

			      strncpy((char*)msg, "writing flight.csv to SD...\n", sizeof(msg));
			      com_send(&com_conf, msg, strlen((char*)msg), UTF_ENC);
			      osDelay(10);

			      osThreadResume(controlTaskHandle);
			      osThreadResume(loggerTaskHandle);
			      osThreadResume(telemetryTaskHandle);
			      osThreadResume(transferTaskHandle);

				  motor_set(&motor1_conf, 0);
				  motor_set(&motor2_conf, 0);
				  servo_set(&servox_conf, LQR_SSO);
				  servo_set(&servoy_conf, LQR_SSO);

			      uint8_t trigger = 1;
			      osMessageQueuePut(transferQueueHandle, &trigger, 0, 0);
			      break;
			  }

			  case CMD_DATA: {
				  float new_cmd_ref[3] = {0};
				  osMutexAcquire(stateMutexHandle, osWaitForever);
				  new_cmd_ref[0] = cmd.cmd0; // m
				  new_cmd_ref[1] = cmd.cmd1; // m
				  new_cmd_ref[2] = cmd.cmd2; // m
				  memcpy(cmd_ref, new_cmd_ref, sizeof(new_cmd_ref));
				  osMutexRelease(stateMutexHandle);
				  break;
			  }

			  case CMD_TRIM: {
				  osMutexAcquire(stateMutexHandle, osWaitForever);
				  if (cmd.trim_x == cmd.trim_x) servox_conf.offset = (int) cmd.trim_x;
				  if (cmd.trim_y == cmd.trim_y) servoy_conf.offset = (int) cmd.trim_y;
				  osMutexRelease(stateMutexHandle);

				  servo_set(&servox_conf, LQR_SSO);
				  servo_set(&servoy_conf, LQR_SSO);

				  int len = snprintf((char*)msg, sizeof(msg), "TRIM: x=%d y=%d\n", servox_conf.offset, servoy_conf.offset);
				  com_send(&com_conf, msg, len, UTF_ENC);
				  osDelay(10);
				  break;
			  }

			  case CMD_PIDP: {
				  osMutexAcquire(stateMutexHandle, osWaitForever);
				  if (cmd.vkp == cmd.vkp) {
					  vel_pid_x.kp = -cmd.vkp;
					  vel_pid_y.kp = cmd.vkp;
				  }
				  if (cmd.vki == cmd.vki) {
					  vel_pid_x.ki = -cmd.vki;
					  vel_pid_y.ki = cmd.vki;
				  }
				  if (cmd.vkd == cmd.vkd) {
					  vel_pid_x.kd = -cmd.vkd;
					  vel_pid_y.kd = cmd.vkd;
				  }
				  if (cmd.pkp == cmd.pkp) {
					  pos_p_x.kp = cmd.pkp;
					  pos_p_y.kp = cmd.pkp;
				  }
				  pid_reset(&vel_pid_x);
				  pid_reset(&vel_pid_y);

				  osMutexRelease(stateMutexHandle);

				  int len = snprintf((char*)msg, sizeof(msg), "PID: vkp=%.3f vki=%.3f vkd=%.3f pkp=%.3f\n", vel_pid_y.kp, vel_pid_y.ki, vel_pid_y.kd, pos_p_x.kp);
				  com_send(&com_conf, msg, len, UTF_ENC);
				  osDelay(10);
				  break;
			  }

			  case CMD_OFFSET: {
				  osMutexAcquire(stateMutexHandle, osWaitForever);
				  if (cmd.offset_rx == cmd.offset_rx) ref_rx_offset = cmd.offset_rx;
				  if (cmd.offset_ry == cmd.offset_ry) ref_ry_offset = cmd.offset_ry;
				  if (cmd.offset_rz == cmd.offset_rz) ref_rz_offset = cmd.offset_rz;
				  if (cmd.offset_pz == cmd.offset_pz) ref_pz_offset = cmd.offset_pz;

				  int len = snprintf((char*)msg, sizeof(msg), "OFFSET: rx=%.3f ry=%.3f rz=%.2f pz=%.3f\n", ref_rx_offset, ref_ry_offset, ref_rz_offset, ref_pz_offset);
				  osMutexRelease(stateMutexHandle);

				  com_send(&com_conf, msg, len, UTF_ENC);
				  osDelay(10);
				  break;
			  }

			  default:
				  break;
			}
	}
	}
  /* USER CODE END CommandTask */
}

void LoggerTask(void *argument)
{
  /* USER CODE BEGIN LoggerTask */
	/* Infinite loop */
	for(;;)
	{
	flight_log_t entry;

	if (osMessageQueueGet(loggerQueueHandle, &entry, NULL, osWaitForever) == osOK) {
	  osMutexAcquire(spi1MutexHandle, osWaitForever);
	  log_to_flash(&entry);
	  osMutexRelease(spi1MutexHandle);
	}
	}
  /* USER CODE END LoggerTask */
}

void TelemetryTask(void *argument)
{
  /* USER CODE BEGIN TelemetryTask */

	telemetry_packet_t pkt;
	uint8_t buf[TELEMETRY_PAYLOAD_LEN];
	/* Infinite loop */
	for(;;)
	{
		if (osMessageQueueGet(telemetryQueueHandle, &pkt, NULL, osWaitForever) == osOK) {
		  uint8_t idx = 0;
		  memcpy(buf + idx, &pkt.accel.axis.x, 4); idx += 4;
		  memcpy(buf + idx, &pkt.accel.axis.y, 4); idx += 4;
		  memcpy(buf + idx, &pkt.accel.axis.z, 4); idx += 4;
		  memcpy(buf + idx, &pkt.gyro.axis.x,  4); idx += 4;
		  memcpy(buf + idx, &pkt.gyro.axis.y,  4); idx += 4;
		  memcpy(buf + idx, &pkt.gyro.axis.z,  4); idx += 4;
		  memcpy(buf + idx, &pkt.mag.axis.x,   4); idx += 4;
		  memcpy(buf + idx, &pkt.mag.axis.y,   4); idx += 4;
		  memcpy(buf + idx, &pkt.mag.axis.z,   4); idx += 4;
		  memcpy(buf + idx, &pkt.flow_dx, 4); idx += 4;
		  memcpy(buf + idx, &pkt.flow_dy, 4); idx += 4;
		  memcpy(buf + idx, &pkt.baro_altitude_m, 4); idx += 4;
		  memcpy(buf + idx, &pkt.tof_altitude_m,  4); idx += 4;
		  memcpy(buf + idx, &pkt.bus_voltage_V,   4); idx += 4;
		  memcpy(buf + idx, &pkt.pos.axis.x, 4); idx += 4;
		  memcpy(buf + idx, &pkt.pos.axis.y, 4); idx += 4;
		  memcpy(buf + idx, &pkt.pos.axis.z, 4); idx += 4;
		  memcpy(buf + idx, &pkt.ori.angle.roll,  4); idx += 4;
		  memcpy(buf + idx, &pkt.ori.angle.pitch, 4); idx += 4;
		  memcpy(buf + idx, &pkt.ori.angle.yaw,   4); idx += 4;

		  com_send(&com_conf, buf, idx, ACCEL_ENC | GYRO_ENC | MAG_ENC | FLOW_ENC | BARNTOF_ENC | POW_ENC | POS_ENC | ORI_ENC);
		}
	}
  /* USER CODE END TelemetryTask */
}

void TransferTask(void *argument)
{
  /* USER CODE BEGIN TransferTask */
  uint8_t trigger;
  for (;;)
	{
	  if (osMessageQueueGet(transferQueueHandle, &trigger, NULL, osWaitForever) == osOK) {

		osMutexAcquire(spi1MutexHandle, osWaitForever);

		osThreadSuspend(controlTaskHandle);
		osThreadSuspend(commandTaskHandle);
		osThreadSuspend(loggerTaskHandle);
		osThreadSuspend(telemetryTaskHandle);

		uint8_t success = transfer_logs_to_sd();

		osMutexRelease(spi1MutexHandle);

		// Reset the time delta flag to prevent a massive delta_time calculation
		// on the first loop after resuming the control task.
		osMutexAcquire(stateMutexHandle, osWaitForever);
		dt_init = false;
		rz_unwrap_init = false;
		osMutexRelease(stateMutexHandle);

		osThreadResume(controlTaskHandle);
		osThreadResume(commandTaskHandle);
		osThreadResume(loggerTaskHandle);
		osThreadResume(telemetryTaskHandle);

		uint8_t msg[32];
		uint8_t len = snprintf((char*)msg, sizeof(msg), success ? "write complete!\n" : "write FAILED!\n");
		com_send(&com_conf, msg, len, UTF_ENC);
	  }
	}
  /* USER CODE END TransferTask */
}
